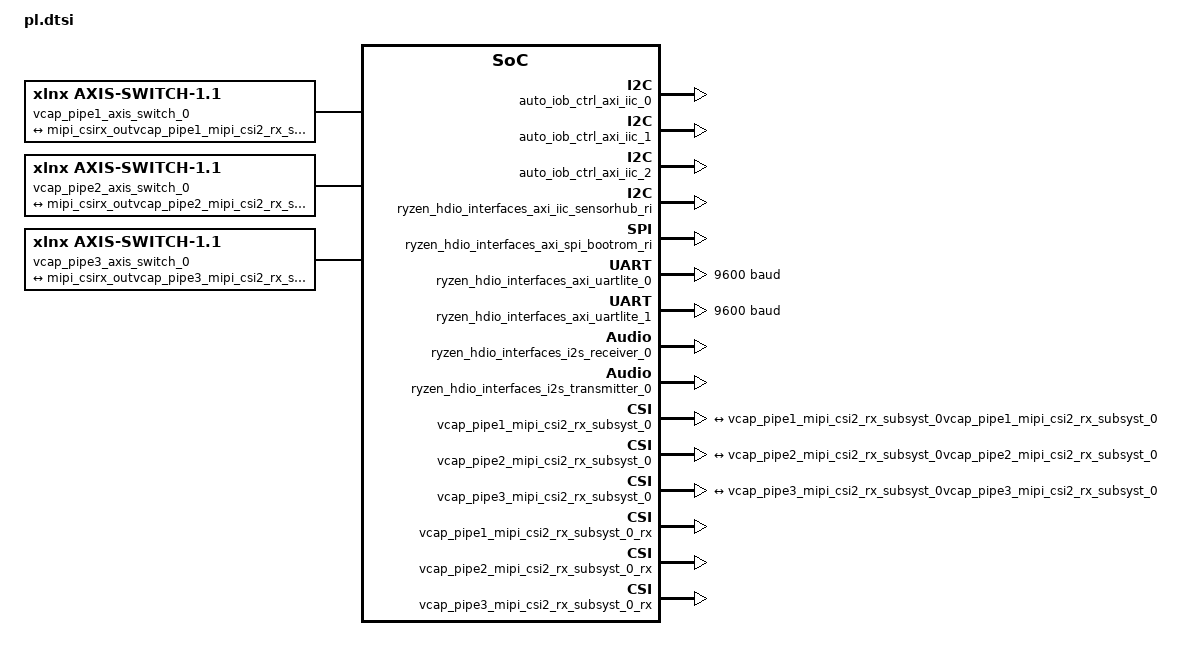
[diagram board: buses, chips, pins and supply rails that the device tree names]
/dts-v1/;
/plugin/;
&fpga {
	firmware-name = "versal_hexcam_20232_1_pld.pdi";
	misc_clk_2: misc_clk_2 {
		compatible = "fixed-clock";
		clock-frequency = <249997499>;
		#clock-cells = <0>;
	};
	misc_clk_0: misc_clk_0 {
		compatible = "fixed-clock";
		clock-frequency = <99999000>;
		#clock-cells = <0>;
	};
	misc_clk_4: misc_clk_4 {
		compatible = "fixed-clock";
		clock-frequency = <125000000>;
		#clock-cells = <0>;
	};
	misc_clk_1: misc_clk_1 {
		compatible = "fixed-clock";
		clock-frequency = <199998000>;
		#clock-cells = <0>;
	};
	misc_clk_3: misc_clk_3 {
		compatible = "fixed-clock";
		clock-frequency = <100000000>;
		#clock-cells = <0>;
	};
};

&amba {
	axi_intc_0: interrupt-controller@b01b0000 {
		#interrupt-cells = <2>;
		interrupts = < 0 143 4 >;
		xlnx,sense-of-irq-edge-type = "Rising";
		xlnx,edk-special = "INTR_CTRL";
		xlnx,kind-of-intr = <0x300>;
		xlnx,kind-of-edge = <0xffffffff>;
		xlnx,irq-is-level = <1>;
		xlnx,has-ivr = <1>;
		compatible = "xlnx,axi-intc-4.1" , "xlnx,xps-intc-1.00.a";
		xlnx,disable-synchronizers = <0>;
		xlnx,kind-of-lvl = <0xffffffff>;
		xlnx,ivar-reset-value = <0x10>;
		xlnx,irq-active = <0x1>;
		interrupt-parent = <&gic>;
		xlnx,en-cascade-mode = <0>;
		xlnx,ip-name = "axi_intc";
		xlnx,has-ilr = <0>;
		reg = <0x0 0xb01b0000 0x0 0x10000>;
		xlnx,addr-width = <0x20>;
		clocks = <&misc_clk_0>;
		xlnx,s-axi-aclk-freq-mhz = <0x5f5dd18>;
		xlnx,num-sw-intr = <0>;
		xlnx,irq-connection = <1>;
		xlnx,num-intr-inputs = <0x16>;
		xlnx,has-sie = <1>;
		xlnx,enable-async = <0>;
		xlnx,has-cie = <1>;
		xlnx,num-sync-ff = <2>;
		xlnx,edk-iptype = "PERIPHERAL";
		xlnx,mb-clk-not-connected = <1>;
		xlnx,has-ipr = <1>;
		xlnx,sense-of-irq-level-type = "Active_High";
		xlnx,cascade-master = <0>;
		xlnx,processor-clk-freq-mhz = <100>;
		xlnx,is-fast = <0x0>;
		clock-names = "s_axi_aclk";
		xlnx,has-fast = <0>;
		xlnx,ivar-rst-val = <0x10>;
		interrupt-controller;
		interrupt-names = "irq";
		xlnx,async-intr = <0xffcffff8>;
		xlnx,name = "axi_intc_0";
	};
	auto_iob_ctrl_axi_gpio_0: gpio@b0130000 {
		xlnx,gpio-board-interface = "Custom";
		compatible = "xlnx,axi-gpio-2.0" , "xlnx,xps-gpio-1.00.a";
		xlnx,all-outputs = <0>;
		#gpio-cells = <2>;
		xlnx,gpio-width = <24>;
		xlnx,dout-default = <0x24042>;
		xlnx,is-dual = <0>;
		xlnx,ip-name = "axi_gpio";
		xlnx,tri-default-2 = <0xffffffff>;
		reg = <0x0 0xb0130000 0x0 0x10000>;
		xlnx,all-inputs-2 = <0>;
		clocks = <&misc_clk_0>;
		xlnx,all-outputs-2 = <0>;
		gpio-controller;
		xlnx,interrupt-present = <0>;
		xlnx,gpio2-board-interface = "Custom";
		xlnx,edk-iptype = "PERIPHERAL";
		xlnx,dout-default-2 = <0x0>;
		xlnx,gpio2-width = <32>;
		clock-names = "s_axi_aclk";
		xlnx,tri-default = <0xf00>;
		xlnx,name = "auto_iob_ctrl_axi_gpio_0";
		xlnx,all-inputs = <0>;
	};
	auto_iob_ctrl_axi_gpio_1: gpio@b0140000 {
		xlnx,gpio-board-interface = "Custom";
		compatible = "xlnx,axi-gpio-2.0" , "xlnx,xps-gpio-1.00.a";
		xlnx,all-outputs = <0>;
		#gpio-cells = <2>;
		xlnx,gpio-width = <5>;
		xlnx,dout-default = <0x0>;
		xlnx,is-dual = <0>;
		xlnx,ip-name = "axi_gpio";
		xlnx,tri-default-2 = <0xffffffff>;
		reg = <0x0 0xb0140000 0x0 0x10000>;
		xlnx,all-inputs-2 = <0>;
		clocks = <&misc_clk_0>;
		xlnx,all-outputs-2 = <0>;
		gpio-controller;
		xlnx,interrupt-present = <0>;
		xlnx,gpio2-board-interface = "Custom";
		xlnx,edk-iptype = "PERIPHERAL";
		xlnx,dout-default-2 = <0x0>;
		xlnx,gpio2-width = <32>;
		clock-names = "s_axi_aclk";
		xlnx,tri-default = <0xffffffff>;
		xlnx,name = "auto_iob_ctrl_axi_gpio_1";
		xlnx,all-inputs = <0>;
	};
	auto_iob_ctrl_axi_gpio_2: gpio@b0150000 {
		xlnx,gpio-board-interface = "Custom";
		compatible = "xlnx,axi-gpio-2.0" , "xlnx,xps-gpio-1.00.a";
		xlnx,all-outputs = <0>;
		#gpio-cells = <2>;
		xlnx,gpio-width = <5>;
		xlnx,dout-default = <0x0>;
		xlnx,is-dual = <0>;
		xlnx,ip-name = "axi_gpio";
		xlnx,tri-default-2 = <0xffffffff>;
		reg = <0x0 0xb0150000 0x0 0x10000>;
		xlnx,all-inputs-2 = <0>;
		clocks = <&misc_clk_0>;
		xlnx,all-outputs-2 = <0>;
		gpio-controller;
		xlnx,interrupt-present = <0>;
		xlnx,gpio2-board-interface = "Custom";
		xlnx,edk-iptype = "PERIPHERAL";
		xlnx,dout-default-2 = <0x0>;
		xlnx,gpio2-width = <32>;
		clock-names = "s_axi_aclk";
		xlnx,tri-default = <0xffffffff>;
		xlnx,name = "auto_iob_ctrl_axi_gpio_2";
		xlnx,all-inputs = <0>;
	};
	auto_iob_ctrl_axi_gpio_3: gpio@b0160000 {
		xlnx,gpio-board-interface = "Custom";
		compatible = "xlnx,axi-gpio-2.0" , "xlnx,xps-gpio-1.00.a";
		xlnx,all-outputs = <0>;
		#gpio-cells = <2>;
		xlnx,gpio-width = <6>;
		xlnx,dout-default = <0x0>;
		xlnx,is-dual = <0>;
		xlnx,ip-name = "axi_gpio";
		xlnx,tri-default-2 = <0xffffffff>;
		reg = <0x0 0xb0160000 0x0 0x10000>;
		xlnx,all-inputs-2 = <0>;
		clocks = <&misc_clk_0>;
		xlnx,all-outputs-2 = <0>;
		gpio-controller;
		xlnx,interrupt-present = <0>;
		xlnx,gpio2-board-interface = "Custom";
		xlnx,edk-iptype = "PERIPHERAL";
		xlnx,dout-default-2 = <0x0>;
		xlnx,gpio2-width = <32>;
		clock-names = "s_axi_aclk";
		xlnx,tri-default = <0xffffffff>;
		xlnx,name = "auto_iob_ctrl_axi_gpio_3";
		xlnx,all-inputs = <0>;
	};
	auto_iob_ctrl_axi_iic_0: i2c@b0170000 {
		interrupts = < 0 2 >;
		xlnx,iic-freq-khz = <100>;
		compatible = "xlnx,axi-iic-2.1" , "xlnx,xps-iic-2.00.a";
		xlnx,scl-inertial-delay = <0>;
		interrupt-parent = <&axi_intc_0>;
		xlnx,ip-name = "axi_iic";
		xlnx,disable-setup-violation-check = <0>;
		reg = <0x0 0xb0170000 0x0 0x10000>;
		clocks = <&misc_clk_0>;
		xlnx,gpo-width = <1>;
		xlnx,edk-iptype = "PERIPHERAL";
		xlnx,static-timing-reg-width = <0>;
		xlnx,sda-level = <1>;
		clock-names = "s_axi_aclk";
		xlnx,ten-bit-adr = <0>;
		xlnx,default-value = <0x0>;
		interrupt-names = "iic2intc_irpt";
		xlnx,iic-board-interface = "Custom";
		xlnx,timing-reg-width = <32>;
		xlnx,iic-freq = <100000>;
		xlnx,smbus-pmbus-host = <0>;
		xlnx,name = "auto_iob_ctrl_axi_iic_0";
		xlnx,axi-aclk-freq-mhz = <0x5f5dd18>;
		xlnx,sda-inertial-delay = <0>;
	};
	auto_iob_ctrl_axi_iic_1: i2c@b0180000 {
		interrupts = < 1 2 >;
		xlnx,iic-freq-khz = <100>;
		compatible = "xlnx,axi-iic-2.1" , "xlnx,xps-iic-2.00.a";
		xlnx,scl-inertial-delay = <0>;
		interrupt-parent = <&axi_intc_0>;
		xlnx,ip-name = "axi_iic";
		xlnx,disable-setup-violation-check = <0>;
		reg = <0x0 0xb0180000 0x0 0x10000>;
		clocks = <&misc_clk_0>;
		xlnx,gpo-width = <1>;
		xlnx,edk-iptype = "PERIPHERAL";
		xlnx,static-timing-reg-width = <0>;
		xlnx,sda-level = <1>;
		clock-names = "s_axi_aclk";
		xlnx,ten-bit-adr = <0>;
		xlnx,default-value = <0x0>;
		interrupt-names = "iic2intc_irpt";
		xlnx,iic-board-interface = "Custom";
		xlnx,timing-reg-width = <32>;
		xlnx,iic-freq = <100000>;
		xlnx,smbus-pmbus-host = <0>;
		xlnx,name = "auto_iob_ctrl_axi_iic_1";
		xlnx,axi-aclk-freq-mhz = <0x5f5dd18>;
		xlnx,sda-inertial-delay = <0>;
	};
	auto_iob_ctrl_axi_iic_2: i2c@b0190000 {
		interrupts = < 2 2 >;
		xlnx,iic-freq-khz = <100>;
		compatible = "xlnx,axi-iic-2.1" , "xlnx,xps-iic-2.00.a";
		xlnx,scl-inertial-delay = <0>;
		interrupt-parent = <&axi_intc_0>;
		xlnx,ip-name = "axi_iic";
		xlnx,disable-setup-violation-check = <0>;
		reg = <0x0 0xb0190000 0x0 0x10000>;
		clocks = <&misc_clk_0>;
		xlnx,gpo-width = <1>;
		xlnx,edk-iptype = "PERIPHERAL";
		xlnx,static-timing-reg-width = <0>;
		xlnx,sda-level = <1>;
		clock-names = "s_axi_aclk";
		xlnx,ten-bit-adr = <0>;
		xlnx,default-value = <0x0>;
		interrupt-names = "iic2intc_irpt";
		xlnx,iic-board-interface = "Custom";
		xlnx,timing-reg-width = <32>;
		xlnx,iic-freq = <100000>;
		xlnx,smbus-pmbus-host = <0>;
		xlnx,name = "auto_iob_ctrl_axi_iic_2";
		xlnx,axi-aclk-freq-mhz = <0x5f5dd18>;
		xlnx,sda-inertial-delay = <0>;
	};
	axi_gpio_rst: gpio@b01a0000 {
		xlnx,gpio-board-interface = "Custom";
		compatible = "xlnx,axi-gpio-2.0" , "xlnx,xps-gpio-1.00.a";
		xlnx,all-outputs = <1>;
		#gpio-cells = <2>;
		xlnx,gpio-width = <32>;
		xlnx,dout-default = <0xffffffff>;
		xlnx,is-dual = <0>;
		xlnx,ip-name = "axi_gpio";
		xlnx,tri-default-2 = <0xffffffff>;
		reg = <0x0 0xb01a0000 0x0 0x10000>;
		xlnx,all-inputs-2 = <0>;
		clocks = <&misc_clk_0>;
		xlnx,all-outputs-2 = <0>;
		gpio-controller;
		xlnx,interrupt-present = <0>;
		xlnx,gpio2-board-interface = "Custom";
		xlnx,edk-iptype = "PERIPHERAL";
		xlnx,dout-default-2 = <0x0>;
		xlnx,gpio2-width = <32>;
		clock-names = "s_axi_aclk";
		xlnx,tri-default = <0xffffffff>;
		xlnx,name = "axi_gpio_rst";
		xlnx,all-inputs = <0>;
	};
	messaging_axi_bram_ctrl_0: messaging_axi_bram_ctrl_0@80100000000 {
		xlnx,protocol = "AXI4";
		xlnx,edk-special = "BRAM_CTRL";
		compatible = "xlnx,axi-bram-ctrl-4.1" , "xlnx,axi-bram-ctrl";
		xlnx,ecc-onoff-reset-value = <0>;
		xlnx,ecc-type = <0>;
		xlnx,rd-cmd-optimization = <0>;
		xlnx,memory-depth = <2048>;
		xlnx,use-ecc = <0>;
		xlnx,fault-inject = <0>;
		xlnx,ip-name = "axi_bram_ctrl";
		reg = <0x00000801 0x00000000 0x0 0x2000>;
		xlnx,bmg-instance = "EXTERNAL";
		clocks = <&misc_clk_0>;
		xlnx,s-axi-ctrl-addr-width = <32>;
		xlnx,read-latency = <1>;
		xlnx,id-width = <0>;
		xlnx,s-axi-supports-narrow-burst = <0>;
		xlnx,supports-narrow-burst = <0>;
		xlnx,single-port-bram = <1>;
		xlnx,ecc = <0>;
		xlnx,edk-iptype = "PERIPHERAL";
		clock-names = "s_axi_aclk";
		xlnx,data-width = <32>;
		xlnx,bram-addr-width = <11>;
		xlnx,bram-inst-mode = "EXTERNAL";
		xlnx,s-axi-ctrl-data-width = <32>;
		xlnx,mem-depth = <2048>;
		xlnx,s-axi-id-width = <1>;
		xlnx,name = "messaging_axi_bram_ctrl_0";
	};
	messaging_axi_bram_ctrl_1: messaging_axi_bram_ctrl_1@80100002000 {
		xlnx,protocol = "AXI4";
		xlnx,edk-special = "BRAM_CTRL";
		compatible = "xlnx,axi-bram-ctrl-4.1" , "xlnx,axi-bram-ctrl";
		xlnx,ecc-onoff-reset-value = <0>;
		xlnx,ecc-type = <0>;
		xlnx,rd-cmd-optimization = <0>;
		xlnx,memory-depth = <2048>;
		xlnx,use-ecc = <0>;
		xlnx,fault-inject = <0>;
		xlnx,ip-name = "axi_bram_ctrl";
		reg = <0x00000801 0x00002000 0x0 0x2000>;
		xlnx,bmg-instance = "EXTERNAL";
		clocks = <&misc_clk_0>;
		xlnx,s-axi-ctrl-addr-width = <32>;
		xlnx,read-latency = <1>;
		xlnx,id-width = <0>;
		xlnx,s-axi-supports-narrow-burst = <0>;
		xlnx,supports-narrow-burst = <0>;
		xlnx,single-port-bram = <1>;
		xlnx,ecc = <0>;
		xlnx,edk-iptype = "PERIPHERAL";
		clock-names = "s_axi_aclk";
		xlnx,data-width = <32>;
		xlnx,bram-addr-width = <11>;
		xlnx,bram-inst-mode = "EXTERNAL";
		xlnx,s-axi-ctrl-data-width = <32>;
		xlnx,mem-depth = <2048>;
		xlnx,s-axi-id-width = <1>;
		xlnx,name = "messaging_axi_bram_ctrl_1";
	};
	messaging_axi_gpio_0: gpio@80100005000 {
		xlnx,gpio-board-interface = "Custom";
		compatible = "xlnx,axi-gpio-2.0" , "xlnx,xps-gpio-1.00.a";
		xlnx,all-outputs = <1>;
		#gpio-cells = <2>;
		xlnx,gpio-width = <2>;
		xlnx,dout-default = <0x0>;
		xlnx,is-dual = <0>;
		xlnx,ip-name = "axi_gpio";
		xlnx,tri-default-2 = <0xffffffff>;
		reg = <0x00000801 0x00005000 0x0 0x1000>;
		xlnx,all-inputs-2 = <0>;
		clocks = <&misc_clk_0>;
		xlnx,all-outputs-2 = <0>;
		gpio-controller;
		xlnx,interrupt-present = <0>;
		xlnx,gpio2-board-interface = "Custom";
		xlnx,edk-iptype = "PERIPHERAL";
		xlnx,dout-default-2 = <0x0>;
		xlnx,gpio2-width = <32>;
		clock-names = "s_axi_aclk";
		xlnx,tri-default = <0xffffffff>;
		xlnx,name = "messaging_axi_gpio_0";
		xlnx,all-inputs = <0>;
	};
	messaging_axi_gpio_1: gpio@80100004000 {
		xlnx,gpio-board-interface = "Custom";
		compatible = "xlnx,axi-gpio-2.0" , "xlnx,xps-gpio-1.00.a";
		xlnx,all-outputs = <1>;
		#gpio-cells = <2>;
		xlnx,gpio-width = <2>;
		xlnx,dout-default = <0x0>;
		xlnx,is-dual = <0>;
		xlnx,ip-name = "axi_gpio";
		xlnx,tri-default-2 = <0xffffffff>;
		reg = <0x00000801 0x00004000 0x0 0x1000>;
		xlnx,all-inputs-2 = <0>;
		clocks = <&misc_clk_0>;
		xlnx,all-outputs-2 = <0>;
		gpio-controller;
		xlnx,interrupt-present = <0>;
		xlnx,gpio2-board-interface = "Custom";
		xlnx,edk-iptype = "PERIPHERAL";
		xlnx,dout-default-2 = <0x0>;
		xlnx,gpio2-width = <32>;
		clock-names = "s_axi_aclk";
		xlnx,tri-default = <0xffffffff>;
		xlnx,name = "messaging_axi_gpio_1";
		xlnx,all-inputs = <0>;
	};
	ryzen_hdio_interfaces_axi_gpio_0: gpio@b01c0000 {
		xlnx,gpio-board-interface = "Custom";
		compatible = "xlnx,axi-gpio-2.0" , "xlnx,xps-gpio-1.00.a";
		xlnx,all-outputs = <0>;
		#gpio-cells = <2>;
		xlnx,gpio-width = <2>;
		xlnx,dout-default = <0x0>;
		xlnx,is-dual = <0>;
		xlnx,ip-name = "axi_gpio";
		xlnx,tri-default-2 = <0xffffffff>;
		reg = <0x0 0xb01c0000 0x0 0x10000>;
		xlnx,all-inputs-2 = <0>;
		clocks = <&misc_clk_0>;
		xlnx,all-outputs-2 = <0>;
		gpio-controller;
		xlnx,interrupt-present = <0>;
		xlnx,gpio2-board-interface = "Custom";
		xlnx,edk-iptype = "PERIPHERAL";
		xlnx,dout-default-2 = <0x0>;
		xlnx,gpio2-width = <32>;
		clock-names = "s_axi_aclk";
		xlnx,tri-default = <0xffffffff>;
		xlnx,name = "ryzen_hdio_interfaces_axi_gpio_0";
		xlnx,all-inputs = <0>;
	};
	ryzen_hdio_interfaces_axi_gpio_bootrom_ri: gpio@b01d0000 {
		xlnx,gpio-board-interface = "Custom";
		compatible = "xlnx,axi-gpio-2.0" , "xlnx,xps-gpio-1.00.a";
		xlnx,all-outputs = <0>;
		#gpio-cells = <2>;
		xlnx,gpio-width = <1>;
		xlnx,dout-default = <0x0>;
		xlnx,is-dual = <0>;
		xlnx,ip-name = "axi_gpio";
		xlnx,tri-default-2 = <0xffffffff>;
		reg = <0x0 0xb01d0000 0x0 0x10000>;
		xlnx,all-inputs-2 = <0>;
		clocks = <&misc_clk_0>;
		xlnx,all-outputs-2 = <0>;
		gpio-controller;
		xlnx,interrupt-present = <0>;
		xlnx,gpio2-board-interface = "Custom";
		xlnx,edk-iptype = "PERIPHERAL";
		xlnx,dout-default-2 = <0x0>;
		xlnx,gpio2-width = <32>;
		clock-names = "s_axi_aclk";
		xlnx,tri-default = <0xffffffff>;
		xlnx,name = "ryzen_hdio_interfaces_axi_gpio_bootrom_ri";
		xlnx,all-inputs = <0>;
	};
	ryzen_hdio_interfaces_axi_gpio_sensorhub_ri: gpio@b01e0000 {
		xlnx,gpio-board-interface = "Custom";
		compatible = "xlnx,axi-gpio-2.0" , "xlnx,xps-gpio-1.00.a";
		xlnx,all-outputs = <0>;
		#gpio-cells = <2>;
		xlnx,gpio-width = <1>;
		xlnx,dout-default = <0x0>;
		xlnx,is-dual = <0>;
		xlnx,ip-name = "axi_gpio";
		xlnx,tri-default-2 = <0xffffffff>;
		reg = <0x0 0xb01e0000 0x0 0x10000>;
		xlnx,all-inputs-2 = <0>;
		clocks = <&misc_clk_0>;
		xlnx,all-outputs-2 = <0>;
		gpio-controller;
		xlnx,interrupt-present = <0>;
		xlnx,gpio2-board-interface = "Custom";
		xlnx,edk-iptype = "PERIPHERAL";
		xlnx,dout-default-2 = <0x0>;
		xlnx,gpio2-width = <32>;
		clock-names = "s_axi_aclk";
		xlnx,tri-default = <0xffffffff>;
		xlnx,name = "ryzen_hdio_interfaces_axi_gpio_sensorhub_ri";
		xlnx,all-inputs = <0>;
	};
	ryzen_hdio_interfaces_axi_iic_sensorhub_ri: i2c@b01f0000 {
		xlnx,iic-freq-khz = <100>;
		compatible = "xlnx,axi-iic-2.1" , "xlnx,xps-iic-2.00.a";
		xlnx,scl-inertial-delay = <0>;
		xlnx,ip-name = "axi_iic";
		xlnx,disable-setup-violation-check = <0>;
		reg = <0x0 0xb01f0000 0x0 0x10000>;
		clocks = <&misc_clk_0>;
		xlnx,gpo-width = <1>;
		xlnx,edk-iptype = "PERIPHERAL";
		xlnx,static-timing-reg-width = <0>;
		xlnx,sda-level = <1>;
		clock-names = "s_axi_aclk";
		xlnx,ten-bit-adr = <0>;
		xlnx,default-value = <0x0>;
		xlnx,iic-board-interface = "Custom";
		xlnx,timing-reg-width = <32>;
		xlnx,iic-freq = <100000>;
		xlnx,smbus-pmbus-host = <0>;
		xlnx,name = "ryzen_hdio_interfaces_axi_iic_sensorhub_ri";
		xlnx,axi-aclk-freq-mhz = <0x5f5dd18>;
		xlnx,sda-inertial-delay = <0>;
	};
	ryzen_hdio_interfaces_axi_spi_bootrom_ri: axi_quad_spi@b0210000 {
		xlnx,select-xpm = <0>;
		compatible = "xlnx,axi-quad-spi-3.2" , "xlnx,xps-spi-2.00.a";
		xlnx,lsb-stup = <0>;
		xlnx,num-ss-bits = <0x1>;
		xlnx,hasfifos = <1>;
		xlnx,xip-mode = <0>;
		xlnx,use-startup-ext = <0>;
		xlnx,s-axi4-addr-width = <24>;
		xlnx,byte-level-interrupt-en = <0>;
		num-cs = <0x1>;
		xlnx,xip-perf-mode = <1>;
		xlnx,sck-ratio = <16>;
		xlnx,s-axi4-id-width = <4>;
		fifo-size = <16>;
		xlnx,multiples16 = <1>;
		xlnx,master-mode = <1>;
		xlnx,shared-startup = <0>;
		xlnx,ip-name = "axi_quad_spi";
		xlnx,qspi-board-interface = "Custom";
		reg = <0x0 0xb0210000 0x0 0x10000>;
		xlnx,dual-quad-mode = <0>;
		xlnx,new-seq-en = <1>;
		bits-per-word = <8>;
		clocks = <&misc_clk_0>, <&misc_clk_0>;
		xlnx,num-transfer-bits = <8>;
		xlnx,spi-memory = <1>;
		xlnx,s-axi4-data-width = <32>;
		xlnx,edk-iptype = "PERIPHERAL";
		xlnx,slaveonly = <0>;
		xlnx,use-startup-int = <0>;
		xlnx,use-startup = <0>;
		xlnx,type-of-axi4-interface = <0>;
		xlnx,async-clk = <0>;
		xlnx,spi-mode = <0>;
		xlnx,sck-ratio1 = <1>;
		xlnx,fifo-depth = <16>;
		clock-names = "ext_spi_clk" , "s_axi_aclk";
		xlnx,uc-family = <0>;
		xlnx,spi-mem-addr-bits = <24>;
		xlnx,axi-interface = <0>;
		xlnx,Axi4-address = <0>;
		xlnx,fifo-included = <1>;
		xlnx,sub-family = "versal";
		xlnx,name = "ryzen_hdio_interfaces_axi_spi_bootrom_ri";
	};
	ryzen_hdio_interfaces_axi_uartlite_0: serial@b0220000 {
		compatible = "xlnx,axi-uartlite-2.0" , "xlnx,xps-uartlite-1.00.a";
		xlnx,uartlite-board-interface = "Custom";
		xlnx,s-axi-aclk-freq-hz-d = <0x5f5dd18>;
		xlnx,ip-name = "axi_uartlite";
		reg = <0x0 0xb0220000 0x0 0x10000>;
		xlnx,baudrate = <9600>;
		clocks = <&misc_clk_0>;
		current-speed = <9600>;
		xlnx,use-parity = <0>;
		xlnx,edk-iptype = "PERIPHERAL";
		xlnx,odd-parity = <0>;
		clock-names = "s_axi_aclk";
		xlnx,name = "ryzen_hdio_interfaces_axi_uartlite_0";
		xlnx,data-bits = <8>;
		xlnx,parity = "No_Parity";
	};
	ryzen_hdio_interfaces_axi_uartlite_1: serial@b0230000 {
		compatible = "xlnx,axi-uartlite-2.0" , "xlnx,xps-uartlite-1.00.a";
		xlnx,uartlite-board-interface = "Custom";
		xlnx,s-axi-aclk-freq-hz-d = <0x5f5dd18>;
		xlnx,ip-name = "axi_uartlite";
		reg = <0x0 0xb0230000 0x0 0x10000>;
		xlnx,baudrate = <9600>;
		clocks = <&misc_clk_0>;
		current-speed = <9600>;
		xlnx,use-parity = <0>;
		xlnx,edk-iptype = "PERIPHERAL";
		xlnx,odd-parity = <0>;
		clock-names = "s_axi_aclk";
		xlnx,name = "ryzen_hdio_interfaces_axi_uartlite_1";
		xlnx,data-bits = <8>;
		xlnx,parity = "No_Parity";
	};
	ryzen_hdio_interfaces_i2s_receiver_0: i2s_receiver@b0010000 {
		aud_mclk = <99999000>;
		interrupts = < 18 2 >;
		compatible = "xlnx,i2s-receiver-1.0" , "xlnx,i2s-receiver-1.0";
		xlnx,dwidth = <0x18>;
		xlnx,depth = <0x80>;
		interrupt-parent = <&axi_intc_0>;
		xlnx,ip-name = "i2s_receiver";
		reg = <0x0 0xb0010000 0x0 0x10000>;
		clocks = <&misc_clk_0>, <&misc_clk_0>, <&misc_clk_0>;
		xlnx,num-channels = <0x1>;
		xlnx,i2srx-board-interface = "Custom";
		xlnx,edk-iptype = "PERIPHERAL";
		xlnx,is-master = <1>;
		clock-names = "aud_mclk" , "m_axis_aud_aclk" , "s_axi_ctrl_aclk";
		xlnx,32bit-lr = <0>;
		interrupt-names = "irq";
		xlnx,name = "ryzen_hdio_interfaces_i2s_receiver_0";
	};
	ryzen_hdio_interfaces_i2s_transmitter_0: i2s_transmitter@b0020000 {
		aud_mclk = <99999000>;
		interrupts = < 19 2 >;
		compatible = "xlnx,i2s-transmitter-1.0" , "xlnx,i2s-transmitter-1.0";
		xlnx,dwidth = <0x18>;
		xlnx,depth = <0x80>;
		interrupt-parent = <&axi_intc_0>;
		xlnx,ip-name = "i2s_transmitter";
		reg = <0x0 0xb0020000 0x0 0x10000>;
		clocks = <&misc_clk_0>, <&misc_clk_0>, <&misc_clk_0>;
		xlnx,num-channels = <0x1>;
		xlnx,edk-iptype = "PERIPHERAL";
		xlnx,is-master = <1>;
		xlnx,i2stx-board-interface = "Custom";
		clock-names = "aud_mclk" , "s_axi_ctrl_aclk" , "s_axis_aud_aclk";
		xlnx,32bit-lr = <0>;
		interrupt-names = "irq";
		xlnx,name = "ryzen_hdio_interfaces_i2s_transmitter_0";
	};
	vcap_pipe1_mipi_csi2_rx_subsyst_0: mipi_csi2_rx_subsystem@b0000000 {
		xlnx,data-lane2-byte = "All_Byte";
		xlnx,dpy-en-reg-if = <1>;
		xlnx,cmn-vc = <4>;
		xlnx,dphy-lanes = <3>;
		xlnx,ip-name = "mipi_csi2_rx_subsystem";
		reg = <0x0 0xb0000000 0x0 0x2000>;
		xlnx,vfb-tu-width = <1>;
		xlnx,ppc = <4>;
		xlnx,csi-buf-depth = <2048>;
		xlnx,exdes-fmc = "LI-IMX274MIPI-FMC , V1.0 , Single , Sensor";
		xlnx,supportlevel = <1>;
		xlnx,clk-lane-io-loc-name = "None";
		xlnx,max-lanes = <3>;
		xlnx,is-versal;
		xlnx,cmn-inc-iic = <0>;
		xlnx,clk-lane-io-loc = "None";
		xlnx,esc-timeout = <25600>;
		interrupt-names = "csirxss_csi_irq";
		xlnx,cmn-inc-vfb;
		xlnx,axis-tuser-width = <96>;
		compatible = "xlnx,mipi-csi2-rx-subsystem-6.0" , "xlnx,mipi-csi2-rx-subsystem-5.0";
		xlnx,en-active-lanes;
		xlnx,idly-tap = <1>;
		dphy-present = <0>;
		xlnx,cmn-num-pixels = <4>;
		xlnx,cmn-proj-family = <0>;
		xlnx,csi2rx-dbg = <0>;
		xlnx,fifo-rd-en-control;
		xlnx,vfb;
		interrupt-parent = <&axi_intc_0>;
		xlnx,data-lane1-io-loc-name = "None";
		xlnx,hs-timeout = <65541>;
		xlnx,data-lane3-io-loc-name = "None";
		xlnx,ext-mmcm = <0>;
		xlnx,data-lane1-byte = "All_Byte";
		xlnx,master-riu;
		xlnx,cal-mode = "NONE";
		rxphy-connected = <&vcap_pipe1_mipi_csi2_rx_subsyst_0_phy>;
		xlnx,mipi-rx-phy-mode = <0>;
		xlnx,data-lane0-io-position = <2>;
		xlnx,exdes-board = "VEK280";
		xlnx,data-lane2-io-position = <6>;
		xlnx,vc = <4>;
		xlnx,en-vcx = <0>;
		xlnx,name = "vcap_pipe1_mipi_csi2_rx_subsyst_0";
		xlnx,csi-emb-non-img = <0>;
		interrupts = < 3 2 >;
		xlnx,dphyrx-board-interface = "Custom";
		xlnx,data-lane3-io-loc = "None";
		xlnx,clock-mask = <39>;
		xlnx,hs-settle-ns = <16>;
		xlnx,en-cnts-byte-clk;
		clocks = <&misc_clk_1>, <&misc_clk_0>, <&misc_clk_2>;
		xlnx,data-lane2-io-loc = "None";
		xlnx,mipi-slv-int = <0>;
		xlnx,is-ksb;
		xlnx,cmn-fifo-rd-en-cntrl;
		xlnx,data-lane3-byte = "All_Byte";
		xlnx,stretch-line-rate = <4500>;
		xlnx,phy-mode = "CPHY";
		xlnx,axis-tdest-width = <4>;
		xlnx,en-csi-v2 = <0>;
		xlnx,edk-iptype = "PERIPHERAL";
		xlnx,init = <100000>;
		xlnx,cmn-pxl-format = <0x18>;
		xlnx,int-qor-check = <0>;
		clock-names = "dphy_clk_200M" , "lite_aclk" , "video_aclk";
		xlnx,data-lane1-io-loc = "None";
		xlnx,data-lane0-byte = "All_Byte";
		xlnx,ooc-vid-clk = <0x65b710>;
		csirx-present = <1>;
		xlnx,yuv420-buf-dpth = <128>;
		xlnx,hp-io-bank-selection = <64>;
		xlnx,idly-group-name = "mipi_csi2rx_idly_group";
		xlnx,lprx-disable-extport = <0>;
		csirx-connected = <&vcap_pipe1_mipi_csi2_rx_subsyst_0_rx>;
		xlnx,highaddr = <0xb0001fff>;
		xlnx,cmn-num-lanes = <3>;
		xlnx,exdes-config = "MIPI_Video_Pipe_Camera_to_Display";
		xlnx,exdesboard-version = <2>;
		xlnx,dphy-preset = "CSI2RX_XLNX";
		xlnx,data-lane0-io-loc-name = "None";
		xlnx,csi-pxl-format = <0x18>;
		xlnx,clk-lane-io-position = <0>;
		xlnx,data-lane2-io-loc-name = "None";
		xlnx,data-lane0-io-loc = "None";
		xlnx,inc-phy;
		xlnx,hs-line-rate = <800>;
		rxphy-present = <1>;
		xlnx,dpy-line-rate = <2500>;
		xlnx,csi-en-crc = <1>;
		xlnx,axis-tdata-width = <32>;
		xlnx,csi-controller-reg-if;
		xlnx,data-lane1-io-position = <4>;
		xlnx,dphy-mode = "SLAVE";
		xlnx,data-lane3-io-position = <8>;
		mipi_csi_portsvcap_pipe1_mipi_csi2_rx_subsyst_0: ports {
			#address-cells = <1>;
			#size-cells = <0>;
			mipi_csi_port1vcap_pipe1_mipi_csi2_rx_subsyst_0: port@1 {
				xlnx,video-width = <8>;
				reg = <1>;
				xlnx,video-format = <12>;
				xlnx,cfa-pattern = "rggb";
				mipi_csirx_outvcap_pipe1_mipi_csi2_rx_subsyst_0: endpoint {
					remote-endpoint = <&vcap_pipe1_mipi_csi2_rx_subsyst_0vcap_pipe1_mipi_csi2_rx_subsyst_0>;
				};
			};
			mipi_csi_port0vcap_pipe1_mipi_csi2_rx_subsyst_0: port@0 {
				xlnx,video-width = <8>;
				reg = <0>;
				xlnx,video-format = <12>;
				xlnx,cfa-pattern = "rggb";
				mipi_csi_invcap_pipe1_mipi_csi2_rx_subsyst_0: endpoint {
					data-lanes = < 1 2 3 >;
				};
			};
		};
	};
	vcap_pipe1_v_frmbuf_wr_0: v_frmbuf_wr@b0030000 {
		xlnx,has-y-uv8 = <1>;
		reset-gpios = <&axi_gpio_rst 6 1>;
		xlnx,max-height = <2160>;
		xlnx,has-bgra8 = <0>;
		xlnx,has-rgba8 = <0>;
		xlnx,ip-name = "v_frmbuf_wr";
		reg = <0x0 0xb0030000 0x0 0x10000>;
		xlnx,s-axi-ctrl-addr-width = <0x7>;
		xlnx,pixels-per-clock = <4>;
		xlnx,samples-per-clock = <4>;
		xlnx,max-nr-planes = <2>;
		xlnx,has-bgr8 = <1>;
		xlnx,has-rgb8 = <1>;
		xlnx,has-y-uv8-420 = <0>;
		xlnx,has-yuyv8 = <1>;
		xlnx,has-y-u-v8 = <0>;
		interrupt-names = "interrupt";
		compatible = "xlnx,v-frmbuf-wr-3.0" , "xlnx,axi-frmbuf-wr-v2.2";
		xlnx,max-width = <3840>;
		xlnx,has-rgb16 = <0>;
		xlnx,vid-formats = "rgb888" , "bgr888" , "xbgr8888" , "xrgb8888" , "uyvy" , "y8" , "vuy888" , "xvuy8888" , "yuyv" , "nv16";
		xlnx,has-bgrx8 = <1>;
		xlnx,has-rgbx8 = <1>;
		xlnx,has-rgbx10 = <0>;
		interrupt-parent = <&axi_intc_0>;
		xlnx,aximm-num-outstanding = <4>;
		xlnx,has-uyvy8 = <1>;
		xlnx,use-uram = <0>;
		xlnx,has-rgbx12 = <0>;
		xlnx,aximm-burst-length = <16>;
		xlnx,aximm-addr-width = <64>;
		xlnx,video-width = <8>;
		xlnx,max-cols = <3840>;
		xlnx,has-yuv8 = <1>;
		xlnx,has-y-uv10-420 = <0>;
		xlnx,has-yuva8 = <0>;
		xlnx,has-y-uv12-420 = <0>;
		xlnx,name = "vcap_pipe1_v_frmbuf_wr_0";
		interrupts = < 4 2 >;
		xlnx,has-y10 = <0>;
		xlnx,has-y-uv16-420 = <0>;
		xlnx,has-y12 = <0>;
		xlnx,has-alpha = <0>;
		xlnx,has-y-u-v10 = <0>;
		clocks = <&misc_clk_2>;
		xlnx,has-y16 = <0>;
		xlnx,dma-align = <32>;
		xlnx,has-y-u-v12 = <0>;
		xlnx,edk-iptype = "PERIPHERAL";
		xlnx,has-interlaced = <0>;
		xlnx,has-yuv16 = <0>;
		xlnx,has-yuvx8 = <1>;
		xlnx,is-tile-format = <0>;
		xlnx,dma-addr-width = <64>;
		clock-names = "ap_clk";
		xlnx,s-axi-ctrl-data-width = <0x20>;
		xlnx,has-y8 = <1>;
		xlnx,has-y-uv10 = <0>;
		xlnx,has-y-uv12 = <0>;
		xlnx,max-rows = <2160>;
		xlnx,has-yuvx10 = <0>;
		#dma-cells = <1>;
		xlnx,has-yuvx12 = <0>;
		xlnx,has-y-uv16 = <0>;
		xlnx,max-data-width = <8>;
		xlnx,has-y-u-v8-420 = <0>;
		xlnx,num-video-components = <3>;
		xlnx,aximm-data-width = <256>;
	};
	vcap_pipe1_v_frmbuf_wr_1: v_frmbuf_wr@b0040000 {
		xlnx,has-y-uv8 = <1>;
		reset-gpios = <&axi_gpio_rst 7 1>;
		xlnx,max-height = <2160>;
		xlnx,has-bgra8 = <0>;
		xlnx,has-rgba8 = <0>;
		xlnx,ip-name = "v_frmbuf_wr";
		reg = <0x0 0xb0040000 0x0 0x10000>;
		xlnx,s-axi-ctrl-addr-width = <0x7>;
		xlnx,pixels-per-clock = <4>;
		xlnx,samples-per-clock = <4>;
		xlnx,max-nr-planes = <2>;
		xlnx,has-bgr8 = <1>;
		xlnx,has-rgb8 = <1>;
		xlnx,has-y-uv8-420 = <0>;
		xlnx,has-yuyv8 = <1>;
		xlnx,has-y-u-v8 = <0>;
		interrupt-names = "interrupt";
		compatible = "xlnx,v-frmbuf-wr-3.0" , "xlnx,axi-frmbuf-wr-v2.2";
		xlnx,max-width = <3840>;
		xlnx,has-rgb16 = <0>;
		xlnx,vid-formats = "rgb888" , "bgr888" , "xbgr8888" , "xrgb8888" , "uyvy" , "y8" , "vuy888" , "xvuy8888" , "yuyv" , "nv16";
		xlnx,has-bgrx8 = <1>;
		xlnx,has-rgbx8 = <1>;
		xlnx,has-rgbx10 = <0>;
		interrupt-parent = <&axi_intc_0>;
		xlnx,aximm-num-outstanding = <4>;
		xlnx,has-uyvy8 = <1>;
		xlnx,use-uram = <0>;
		xlnx,has-rgbx12 = <0>;
		xlnx,aximm-burst-length = <16>;
		xlnx,aximm-addr-width = <64>;
		xlnx,video-width = <8>;
		xlnx,max-cols = <3840>;
		xlnx,has-yuv8 = <1>;
		xlnx,has-y-uv10-420 = <0>;
		xlnx,has-yuva8 = <0>;
		xlnx,has-y-uv12-420 = <0>;
		xlnx,name = "vcap_pipe1_v_frmbuf_wr_1";
		interrupts = < 5 2 >;
		xlnx,has-y10 = <0>;
		xlnx,has-y-uv16-420 = <0>;
		xlnx,has-y12 = <0>;
		xlnx,has-alpha = <0>;
		xlnx,has-y-u-v10 = <0>;
		clocks = <&misc_clk_2>;
		xlnx,has-y16 = <0>;
		xlnx,dma-align = <32>;
		xlnx,has-y-u-v12 = <0>;
		xlnx,edk-iptype = "PERIPHERAL";
		xlnx,has-interlaced = <0>;
		xlnx,has-yuv16 = <0>;
		xlnx,has-yuvx8 = <1>;
		xlnx,is-tile-format = <0>;
		xlnx,dma-addr-width = <64>;
		clock-names = "ap_clk";
		xlnx,s-axi-ctrl-data-width = <0x20>;
		xlnx,has-y8 = <1>;
		xlnx,has-y-uv10 = <0>;
		xlnx,has-y-uv12 = <0>;
		xlnx,max-rows = <2160>;
		xlnx,has-yuvx10 = <0>;
		#dma-cells = <1>;
		xlnx,has-yuvx12 = <0>;
		xlnx,has-y-uv16 = <0>;
		xlnx,max-data-width = <8>;
		xlnx,has-y-u-v8-420 = <0>;
		xlnx,num-video-components = <3>;
		xlnx,aximm-data-width = <256>;
	};
	vcap_pipe1_v_frmbuf_wr_2: v_frmbuf_wr@b0050000 {
		xlnx,has-y-uv8 = <1>;
		reset-gpios = <&axi_gpio_rst 8 1>;
		xlnx,max-height = <2160>;
		xlnx,has-bgra8 = <0>;
		xlnx,has-rgba8 = <0>;
		xlnx,ip-name = "v_frmbuf_wr";
		reg = <0x0 0xb0050000 0x0 0x10000>;
		xlnx,s-axi-ctrl-addr-width = <0x7>;
		xlnx,pixels-per-clock = <4>;
		xlnx,samples-per-clock = <4>;
		xlnx,max-nr-planes = <2>;
		xlnx,has-bgr8 = <1>;
		xlnx,has-rgb8 = <1>;
		xlnx,has-y-uv8-420 = <0>;
		xlnx,has-yuyv8 = <1>;
		xlnx,has-y-u-v8 = <0>;
		interrupt-names = "interrupt";
		compatible = "xlnx,v-frmbuf-wr-3.0" , "xlnx,axi-frmbuf-wr-v2.2";
		xlnx,max-width = <3840>;
		xlnx,has-rgb16 = <0>;
		xlnx,vid-formats = "rgb888" , "bgr888" , "xbgr8888" , "xrgb8888" , "uyvy" , "y8" , "vuy888" , "xvuy8888" , "yuyv" , "nv16";
		xlnx,has-bgrx8 = <1>;
		xlnx,has-rgbx8 = <1>;
		xlnx,has-rgbx10 = <0>;
		interrupt-parent = <&axi_intc_0>;
		xlnx,aximm-num-outstanding = <4>;
		xlnx,has-uyvy8 = <1>;
		xlnx,use-uram = <0>;
		xlnx,has-rgbx12 = <0>;
		xlnx,aximm-burst-length = <16>;
		xlnx,aximm-addr-width = <64>;
		xlnx,video-width = <8>;
		xlnx,max-cols = <3840>;
		xlnx,has-yuv8 = <1>;
		xlnx,has-y-uv10-420 = <0>;
		xlnx,has-yuva8 = <0>;
		xlnx,has-y-uv12-420 = <0>;
		xlnx,name = "vcap_pipe1_v_frmbuf_wr_2";
		interrupts = < 6 2 >;
		xlnx,has-y10 = <0>;
		xlnx,has-y-uv16-420 = <0>;
		xlnx,has-y12 = <0>;
		xlnx,has-alpha = <0>;
		xlnx,has-y-u-v10 = <0>;
		clocks = <&misc_clk_2>;
		xlnx,has-y16 = <0>;
		xlnx,dma-align = <32>;
		xlnx,has-y-u-v12 = <0>;
		xlnx,edk-iptype = "PERIPHERAL";
		xlnx,has-interlaced = <0>;
		xlnx,has-yuv16 = <0>;
		xlnx,has-yuvx8 = <1>;
		xlnx,is-tile-format = <0>;
		xlnx,dma-addr-width = <64>;
		clock-names = "ap_clk";
		xlnx,s-axi-ctrl-data-width = <0x20>;
		xlnx,has-y8 = <1>;
		xlnx,has-y-uv10 = <0>;
		xlnx,has-y-uv12 = <0>;
		xlnx,max-rows = <2160>;
		xlnx,has-yuvx10 = <0>;
		#dma-cells = <1>;
		xlnx,has-yuvx12 = <0>;
		xlnx,has-y-uv16 = <0>;
		xlnx,max-data-width = <8>;
		xlnx,has-y-u-v8-420 = <0>;
		xlnx,num-video-components = <3>;
		xlnx,aximm-data-width = <256>;
	};
	vcap_pipe1_v_frmbuf_wr_3: v_frmbuf_wr@b0060000 {
		xlnx,has-y-uv8 = <1>;
		reset-gpios = <&axi_gpio_rst 9 1>;
		xlnx,max-height = <2160>;
		xlnx,has-bgra8 = <0>;
		xlnx,has-rgba8 = <0>;
		xlnx,ip-name = "v_frmbuf_wr";
		reg = <0x0 0xb0060000 0x0 0x10000>;
		xlnx,s-axi-ctrl-addr-width = <0x7>;
		xlnx,pixels-per-clock = <4>;
		xlnx,samples-per-clock = <4>;
		xlnx,max-nr-planes = <2>;
		xlnx,has-bgr8 = <1>;
		xlnx,has-rgb8 = <1>;
		xlnx,has-y-uv8-420 = <0>;
		xlnx,has-yuyv8 = <1>;
		xlnx,has-y-u-v8 = <0>;
		interrupt-names = "interrupt";
		compatible = "xlnx,v-frmbuf-wr-3.0" , "xlnx,axi-frmbuf-wr-v2.2";
		xlnx,max-width = <3840>;
		xlnx,has-rgb16 = <0>;
		xlnx,vid-formats = "rgb888" , "bgr888" , "xbgr8888" , "xrgb8888" , "uyvy" , "y8" , "vuy888" , "xvuy8888" , "yuyv" , "nv16";
		xlnx,has-bgrx8 = <1>;
		xlnx,has-rgbx8 = <1>;
		xlnx,has-rgbx10 = <0>;
		interrupt-parent = <&axi_intc_0>;
		xlnx,aximm-num-outstanding = <4>;
		xlnx,has-uyvy8 = <1>;
		xlnx,use-uram = <0>;
		xlnx,has-rgbx12 = <0>;
		xlnx,aximm-burst-length = <16>;
		xlnx,aximm-addr-width = <64>;
		xlnx,video-width = <8>;
		xlnx,max-cols = <3840>;
		xlnx,has-yuv8 = <1>;
		xlnx,has-y-uv10-420 = <0>;
		xlnx,has-yuva8 = <0>;
		xlnx,has-y-uv12-420 = <0>;
		xlnx,name = "vcap_pipe1_v_frmbuf_wr_3";
		interrupts = < 7 2 >;
		xlnx,has-y10 = <0>;
		xlnx,has-y-uv16-420 = <0>;
		xlnx,has-y12 = <0>;
		xlnx,has-alpha = <0>;
		xlnx,has-y-u-v10 = <0>;
		clocks = <&misc_clk_2>;
		xlnx,has-y16 = <0>;
		xlnx,dma-align = <32>;
		xlnx,has-y-u-v12 = <0>;
		xlnx,edk-iptype = "PERIPHERAL";
		xlnx,has-interlaced = <0>;
		xlnx,has-yuv16 = <0>;
		xlnx,has-yuvx8 = <1>;
		xlnx,is-tile-format = <0>;
		xlnx,dma-addr-width = <64>;
		clock-names = "ap_clk";
		xlnx,s-axi-ctrl-data-width = <0x20>;
		xlnx,has-y8 = <1>;
		xlnx,has-y-uv10 = <0>;
		xlnx,has-y-uv12 = <0>;
		xlnx,max-rows = <2160>;
		xlnx,has-yuvx10 = <0>;
		#dma-cells = <1>;
		xlnx,has-yuvx12 = <0>;
		xlnx,has-y-uv16 = <0>;
		xlnx,max-data-width = <8>;
		xlnx,has-y-u-v8-420 = <0>;
		xlnx,num-video-components = <3>;
		xlnx,aximm-data-width = <256>;
	};
	vcap_pipe2_mipi_csi2_rx_subsyst_0: mipi_csi2_rx_subsystem@b0004000 {
		xlnx,data-lane2-byte = "All_Byte";
		xlnx,dpy-en-reg-if = <1>;
		xlnx,cmn-vc = <4>;
		xlnx,dphy-lanes = <4>;
		xlnx,ip-name = "mipi_csi2_rx_subsystem";
		reg = <0x0 0xb0004000 0x0 0x2000>;
		xlnx,vfb-tu-width = <1>;
		xlnx,ppc = <4>;
		xlnx,csi-buf-depth = <2048>;
		xlnx,exdes-fmc = "LI-IMX274MIPI-FMC , V1.0 , Single , Sensor";
		xlnx,supportlevel = <1>;
		xlnx,clk-lane-io-loc-name = "None";
		xlnx,max-lanes = <4>;
		xlnx,is-versal;
		xlnx,cmn-inc-iic = <0>;
		xlnx,clk-lane-io-loc = "None";
		xlnx,esc-timeout = <25600>;
		interrupt-names = "csirxss_csi_irq";
		xlnx,cmn-inc-vfb;
		xlnx,axis-tuser-width = <96>;
		compatible = "xlnx,mipi-csi2-rx-subsystem-6.0" , "xlnx,mipi-csi2-rx-subsystem-5.0";
		xlnx,en-active-lanes;
		xlnx,idly-tap = <1>;
		dphy-present = <0>;
		xlnx,cmn-num-pixels = <4>;
		xlnx,cmn-proj-family = <0>;
		xlnx,csi2rx-dbg = <0>;
		xlnx,fifo-rd-en-control;
		xlnx,vfb;
		interrupt-parent = <&axi_intc_0>;
		xlnx,data-lane1-io-loc-name = "None";
		xlnx,hs-timeout = <65541>;
		xlnx,data-lane3-io-loc-name = "None";
		xlnx,ext-mmcm = <0>;
		xlnx,data-lane1-byte = "All_Byte";
		xlnx,master-riu;
		xlnx,cal-mode = "NONE";
		rxphy-connected = <&vcap_pipe2_mipi_csi2_rx_subsyst_0_phy>;
		xlnx,mipi-rx-phy-mode = <1>;
		xlnx,data-lane0-io-position = <2>;
		xlnx,exdes-board = "VEK280";
		xlnx,data-lane2-io-position = <6>;
		xlnx,vc = <4>;
		xlnx,en-vcx = <0>;
		xlnx,name = "vcap_pipe2_mipi_csi2_rx_subsyst_0";
		xlnx,csi-emb-non-img = <0>;
		interrupts = < 8 2 >;
		xlnx,dphyrx-board-interface = "Custom";
		xlnx,data-lane3-io-loc = "None";
		xlnx,clock-mask = <39>;
		xlnx,hs-settle-ns = <25>;
		xlnx,en-cnts-byte-clk;
		clocks = <&misc_clk_1>, <&misc_clk_0>, <&misc_clk_2>;
		xlnx,data-lane2-io-loc = "None";
		xlnx,mipi-slv-int = <0>;
		xlnx,is-ksb;
		xlnx,cmn-fifo-rd-en-cntrl;
		xlnx,data-lane3-byte = "All_Byte";
		xlnx,stretch-line-rate = <4500>;
		xlnx,phy-mode = "DPHY";
		xlnx,axis-tdest-width = <4>;
		xlnx,en-csi-v2 = <0>;
		xlnx,edk-iptype = "PERIPHERAL";
		xlnx,init = <100000>;
		xlnx,cmn-pxl-format = <0x18>;
		xlnx,int-qor-check = <0>;
		clock-names = "dphy_clk_200M" , "lite_aclk" , "video_aclk";
		xlnx,data-lane1-io-loc = "None";
		xlnx,data-lane0-byte = "All_Byte";
		xlnx,ooc-vid-clk = <0x65b710>;
		csirx-present = <1>;
		xlnx,yuv420-buf-dpth = <128>;
		xlnx,hp-io-bank-selection = <64>;
		xlnx,idly-group-name = "mipi_csi2rx_idly_group";
		xlnx,lprx-disable-extport = <0>;
		csirx-connected = <&vcap_pipe2_mipi_csi2_rx_subsyst_0_rx>;
		xlnx,highaddr = <0xb0005fff>;
		xlnx,cmn-num-lanes = <4>;
		xlnx,exdes-config = "MIPI_Video_Pipe_Camera_to_Display";
		xlnx,exdesboard-version = <2>;
		xlnx,dphy-preset = "CSI2RX_XLNX";
		xlnx,data-lane0-io-loc-name = "None";
		xlnx,csi-pxl-format = <0x18>;
		xlnx,clk-lane-io-position = <0>;
		xlnx,data-lane2-io-loc-name = "None";
		xlnx,data-lane0-io-loc = "None";
		xlnx,inc-phy;
		xlnx,hs-line-rate = <800>;
		rxphy-present = <1>;
		xlnx,dpy-line-rate = <2500>;
		xlnx,csi-en-crc = <1>;
		xlnx,axis-tdata-width = <32>;
		xlnx,csi-controller-reg-if;
		xlnx,data-lane1-io-position = <4>;
		xlnx,dphy-mode = "SLAVE";
		xlnx,data-lane3-io-position = <8>;
		mipi_csi_portsvcap_pipe2_mipi_csi2_rx_subsyst_0: ports {
			#address-cells = <1>;
			#size-cells = <0>;
			mipi_csi_port1vcap_pipe2_mipi_csi2_rx_subsyst_0: port@1 {
				xlnx,video-width = <8>;
				reg = <1>;
				xlnx,video-format = <12>;
				xlnx,cfa-pattern = "rggb";
				mipi_csirx_outvcap_pipe2_mipi_csi2_rx_subsyst_0: endpoint {
					remote-endpoint = <&vcap_pipe2_mipi_csi2_rx_subsyst_0vcap_pipe2_mipi_csi2_rx_subsyst_0>;
				};
			};
			mipi_csi_port0vcap_pipe2_mipi_csi2_rx_subsyst_0: port@0 {
				xlnx,video-width = <8>;
				reg = <0>;
				xlnx,video-format = <12>;
				xlnx,cfa-pattern = "rggb";
				mipi_csi_invcap_pipe2_mipi_csi2_rx_subsyst_0: endpoint {
					data-lanes = < 1 2 3 4 >;
				};
			};
		};
	};
	vcap_pipe2_v_frmbuf_wr_0: v_frmbuf_wr@b00b0000 {
		xlnx,has-y-uv8 = <1>;
		reset-gpios = <&axi_gpio_rst 11 1>;
		xlnx,max-height = <2160>;
		xlnx,has-bgra8 = <0>;
		xlnx,has-rgba8 = <0>;
		xlnx,ip-name = "v_frmbuf_wr";
		reg = <0x0 0xb00b0000 0x0 0x10000>;
		xlnx,s-axi-ctrl-addr-width = <0x7>;
		xlnx,pixels-per-clock = <4>;
		xlnx,samples-per-clock = <4>;
		xlnx,max-nr-planes = <2>;
		xlnx,has-bgr8 = <1>;
		xlnx,has-rgb8 = <1>;
		xlnx,has-y-uv8-420 = <0>;
		xlnx,has-yuyv8 = <1>;
		xlnx,has-y-u-v8 = <0>;
		interrupt-names = "interrupt";
		compatible = "xlnx,v-frmbuf-wr-3.0" , "xlnx,axi-frmbuf-wr-v2.2";
		xlnx,max-width = <3840>;
		xlnx,has-rgb16 = <0>;
		xlnx,vid-formats = "rgb888" , "bgr888" , "xbgr8888" , "xrgb8888" , "uyvy" , "y8" , "vuy888" , "xvuy8888" , "yuyv" , "nv16";
		xlnx,has-bgrx8 = <1>;
		xlnx,has-rgbx8 = <1>;
		xlnx,has-rgbx10 = <0>;
		interrupt-parent = <&axi_intc_0>;
		xlnx,aximm-num-outstanding = <4>;
		xlnx,has-uyvy8 = <1>;
		xlnx,use-uram = <0>;
		xlnx,has-rgbx12 = <0>;
		xlnx,aximm-burst-length = <16>;
		xlnx,aximm-addr-width = <64>;
		xlnx,video-width = <8>;
		xlnx,max-cols = <3840>;
		xlnx,has-yuv8 = <1>;
		xlnx,has-y-uv10-420 = <0>;
		xlnx,has-yuva8 = <0>;
		xlnx,has-y-uv12-420 = <0>;
		xlnx,name = "vcap_pipe2_v_frmbuf_wr_0";
		interrupts = < 9 2 >;
		xlnx,has-y10 = <0>;
		xlnx,has-y-uv16-420 = <0>;
		xlnx,has-y12 = <0>;
		xlnx,has-alpha = <0>;
		xlnx,has-y-u-v10 = <0>;
		clocks = <&misc_clk_2>;
		xlnx,has-y16 = <0>;
		xlnx,dma-align = <32>;
		xlnx,has-y-u-v12 = <0>;
		xlnx,edk-iptype = "PERIPHERAL";
		xlnx,has-interlaced = <0>;
		xlnx,has-yuv16 = <0>;
		xlnx,has-yuvx8 = <1>;
		xlnx,is-tile-format = <0>;
		xlnx,dma-addr-width = <64>;
		clock-names = "ap_clk";
		xlnx,s-axi-ctrl-data-width = <0x20>;
		xlnx,has-y8 = <1>;
		xlnx,has-y-uv10 = <0>;
		xlnx,has-y-uv12 = <0>;
		xlnx,max-rows = <2160>;
		xlnx,has-yuvx10 = <0>;
		#dma-cells = <1>;
		xlnx,has-yuvx12 = <0>;
		xlnx,has-y-uv16 = <0>;
		xlnx,max-data-width = <8>;
		xlnx,has-y-u-v8-420 = <0>;
		xlnx,num-video-components = <3>;
		xlnx,aximm-data-width = <256>;
	};
	vcap_pipe2_v_frmbuf_wr_1: v_frmbuf_wr@b00c0000 {
		xlnx,has-y-uv8 = <1>;
		reset-gpios = <&axi_gpio_rst 12 1>;
		xlnx,max-height = <2160>;
		xlnx,has-bgra8 = <0>;
		xlnx,has-rgba8 = <0>;
		xlnx,ip-name = "v_frmbuf_wr";
		reg = <0x0 0xb00c0000 0x0 0x10000>;
		xlnx,s-axi-ctrl-addr-width = <0x7>;
		xlnx,pixels-per-clock = <4>;
		xlnx,samples-per-clock = <4>;
		xlnx,max-nr-planes = <2>;
		xlnx,has-bgr8 = <1>;
		xlnx,has-rgb8 = <1>;
		xlnx,has-y-uv8-420 = <0>;
		xlnx,has-yuyv8 = <1>;
		xlnx,has-y-u-v8 = <0>;
		interrupt-names = "interrupt";
		compatible = "xlnx,v-frmbuf-wr-3.0" , "xlnx,axi-frmbuf-wr-v2.2";
		xlnx,max-width = <3840>;
		xlnx,has-rgb16 = <0>;
		xlnx,vid-formats = "rgb888" , "bgr888" , "xbgr8888" , "xrgb8888" , "uyvy" , "y8" , "vuy888" , "xvuy8888" , "yuyv" , "nv16";
		xlnx,has-bgrx8 = <1>;
		xlnx,has-rgbx8 = <1>;
		xlnx,has-rgbx10 = <0>;
		interrupt-parent = <&axi_intc_0>;
		xlnx,aximm-num-outstanding = <4>;
		xlnx,has-uyvy8 = <1>;
		xlnx,use-uram = <0>;
		xlnx,has-rgbx12 = <0>;
		xlnx,aximm-burst-length = <16>;
		xlnx,aximm-addr-width = <64>;
		xlnx,video-width = <8>;
		xlnx,max-cols = <3840>;
		xlnx,has-yuv8 = <1>;
		xlnx,has-y-uv10-420 = <0>;
		xlnx,has-yuva8 = <0>;
		xlnx,has-y-uv12-420 = <0>;
		xlnx,name = "vcap_pipe2_v_frmbuf_wr_1";
		interrupts = < 10 2 >;
		xlnx,has-y10 = <0>;
		xlnx,has-y-uv16-420 = <0>;
		xlnx,has-y12 = <0>;
		xlnx,has-alpha = <0>;
		xlnx,has-y-u-v10 = <0>;
		clocks = <&misc_clk_2>;
		xlnx,has-y16 = <0>;
		xlnx,dma-align = <32>;
		xlnx,has-y-u-v12 = <0>;
		xlnx,edk-iptype = "PERIPHERAL";
		xlnx,has-interlaced = <0>;
		xlnx,has-yuv16 = <0>;
		xlnx,has-yuvx8 = <1>;
		xlnx,is-tile-format = <0>;
		xlnx,dma-addr-width = <64>;
		clock-names = "ap_clk";
		xlnx,s-axi-ctrl-data-width = <0x20>;
		xlnx,has-y8 = <1>;
		xlnx,has-y-uv10 = <0>;
		xlnx,has-y-uv12 = <0>;
		xlnx,max-rows = <2160>;
		xlnx,has-yuvx10 = <0>;
		#dma-cells = <1>;
		xlnx,has-yuvx12 = <0>;
		xlnx,has-y-uv16 = <0>;
		xlnx,max-data-width = <8>;
		xlnx,has-y-u-v8-420 = <0>;
		xlnx,num-video-components = <3>;
		xlnx,aximm-data-width = <256>;
	};
	vcap_pipe2_v_frmbuf_wr_2: v_frmbuf_wr@b00d0000 {
		xlnx,has-y-uv8 = <1>;
		reset-gpios = <&axi_gpio_rst 13 1>;
		xlnx,max-height = <2160>;
		xlnx,has-bgra8 = <0>;
		xlnx,has-rgba8 = <0>;
		xlnx,ip-name = "v_frmbuf_wr";
		reg = <0x0 0xb00d0000 0x0 0x10000>;
		xlnx,s-axi-ctrl-addr-width = <0x7>;
		xlnx,pixels-per-clock = <4>;
		xlnx,samples-per-clock = <4>;
		xlnx,max-nr-planes = <2>;
		xlnx,has-bgr8 = <1>;
		xlnx,has-rgb8 = <1>;
		xlnx,has-y-uv8-420 = <0>;
		xlnx,has-yuyv8 = <1>;
		xlnx,has-y-u-v8 = <0>;
		interrupt-names = "interrupt";
		compatible = "xlnx,v-frmbuf-wr-3.0" , "xlnx,axi-frmbuf-wr-v2.2";
		xlnx,max-width = <3840>;
		xlnx,has-rgb16 = <0>;
		xlnx,vid-formats = "rgb888" , "bgr888" , "xbgr8888" , "xrgb8888" , "uyvy" , "y8" , "vuy888" , "xvuy8888" , "yuyv" , "nv16";
		xlnx,has-bgrx8 = <1>;
		xlnx,has-rgbx8 = <1>;
		xlnx,has-rgbx10 = <0>;
		interrupt-parent = <&axi_intc_0>;
		xlnx,aximm-num-outstanding = <4>;
		xlnx,has-uyvy8 = <1>;
		xlnx,use-uram = <0>;
		xlnx,has-rgbx12 = <0>;
		xlnx,aximm-burst-length = <16>;
		xlnx,aximm-addr-width = <64>;
		xlnx,video-width = <8>;
		xlnx,max-cols = <3840>;
		xlnx,has-yuv8 = <1>;
		xlnx,has-y-uv10-420 = <0>;
		xlnx,has-yuva8 = <0>;
		xlnx,has-y-uv12-420 = <0>;
		xlnx,name = "vcap_pipe2_v_frmbuf_wr_2";
		interrupts = < 11 2 >;
		xlnx,has-y10 = <0>;
		xlnx,has-y-uv16-420 = <0>;
		xlnx,has-y12 = <0>;
		xlnx,has-alpha = <0>;
		xlnx,has-y-u-v10 = <0>;
		clocks = <&misc_clk_2>;
		xlnx,has-y16 = <0>;
		xlnx,dma-align = <32>;
		xlnx,has-y-u-v12 = <0>;
		xlnx,edk-iptype = "PERIPHERAL";
		xlnx,has-interlaced = <0>;
		xlnx,has-yuv16 = <0>;
		xlnx,has-yuvx8 = <1>;
		xlnx,is-tile-format = <0>;
		xlnx,dma-addr-width = <64>;
		clock-names = "ap_clk";
		xlnx,s-axi-ctrl-data-width = <0x20>;
		xlnx,has-y8 = <1>;
		xlnx,has-y-uv10 = <0>;
		xlnx,has-y-uv12 = <0>;
		xlnx,max-rows = <2160>;
		xlnx,has-yuvx10 = <0>;
		#dma-cells = <1>;
		xlnx,has-yuvx12 = <0>;
		xlnx,has-y-uv16 = <0>;
		xlnx,max-data-width = <8>;
		xlnx,has-y-u-v8-420 = <0>;
		xlnx,num-video-components = <3>;
		xlnx,aximm-data-width = <256>;
	};
	vcap_pipe2_v_frmbuf_wr_3: v_frmbuf_wr@b00e0000 {
		xlnx,has-y-uv8 = <1>;
		reset-gpios = <&axi_gpio_rst 14 1>;
		xlnx,max-height = <2160>;
		xlnx,has-bgra8 = <0>;
		xlnx,has-rgba8 = <0>;
		xlnx,ip-name = "v_frmbuf_wr";
		reg = <0x0 0xb00e0000 0x0 0x10000>;
		xlnx,s-axi-ctrl-addr-width = <0x7>;
		xlnx,pixels-per-clock = <4>;
		xlnx,samples-per-clock = <4>;
		xlnx,max-nr-planes = <2>;
		xlnx,has-bgr8 = <1>;
		xlnx,has-rgb8 = <1>;
		xlnx,has-y-uv8-420 = <0>;
		xlnx,has-yuyv8 = <1>;
		xlnx,has-y-u-v8 = <0>;
		interrupt-names = "interrupt";
		compatible = "xlnx,v-frmbuf-wr-3.0" , "xlnx,axi-frmbuf-wr-v2.2";
		xlnx,max-width = <3840>;
		xlnx,has-rgb16 = <0>;
		xlnx,vid-formats = "rgb888" , "bgr888" , "xbgr8888" , "xrgb8888" , "uyvy" , "y8" , "vuy888" , "xvuy8888" , "yuyv" , "nv16";
		xlnx,has-bgrx8 = <1>;
		xlnx,has-rgbx8 = <1>;
		xlnx,has-rgbx10 = <0>;
		interrupt-parent = <&axi_intc_0>;
		xlnx,aximm-num-outstanding = <4>;
		xlnx,has-uyvy8 = <1>;
		xlnx,use-uram = <0>;
		xlnx,has-rgbx12 = <0>;
		xlnx,aximm-burst-length = <16>;
		xlnx,aximm-addr-width = <64>;
		xlnx,video-width = <8>;
		xlnx,max-cols = <3840>;
		xlnx,has-yuv8 = <1>;
		xlnx,has-y-uv10-420 = <0>;
		xlnx,has-yuva8 = <0>;
		xlnx,has-y-uv12-420 = <0>;
		xlnx,name = "vcap_pipe2_v_frmbuf_wr_3";
		interrupts = < 12 2 >;
		xlnx,has-y10 = <0>;
		xlnx,has-y-uv16-420 = <0>;
		xlnx,has-y12 = <0>;
		xlnx,has-alpha = <0>;
		xlnx,has-y-u-v10 = <0>;
		clocks = <&misc_clk_2>;
		xlnx,has-y16 = <0>;
		xlnx,dma-align = <32>;
		xlnx,has-y-u-v12 = <0>;
		xlnx,edk-iptype = "PERIPHERAL";
		xlnx,has-interlaced = <0>;
		xlnx,has-yuv16 = <0>;
		xlnx,has-yuvx8 = <1>;
		xlnx,is-tile-format = <0>;
		xlnx,dma-addr-width = <64>;
		clock-names = "ap_clk";
		xlnx,s-axi-ctrl-data-width = <0x20>;
		xlnx,has-y8 = <1>;
		xlnx,has-y-uv10 = <0>;
		xlnx,has-y-uv12 = <0>;
		xlnx,max-rows = <2160>;
		xlnx,has-yuvx10 = <0>;
		#dma-cells = <1>;
		xlnx,has-yuvx12 = <0>;
		xlnx,has-y-uv16 = <0>;
		xlnx,max-data-width = <8>;
		xlnx,has-y-u-v8-420 = <0>;
		xlnx,num-video-components = <3>;
		xlnx,aximm-data-width = <256>;
	};
	vcap_pipe3_mipi_csi2_rx_subsyst_0: mipi_csi2_rx_subsystem@b0006000 {
		xlnx,data-lane2-byte = "All_Byte";
		xlnx,dpy-en-reg-if = <1>;
		xlnx,cmn-vc = <4>;
		xlnx,dphy-lanes = <4>;
		xlnx,ip-name = "mipi_csi2_rx_subsystem";
		reg = <0x0 0xb0006000 0x0 0x2000>;
		xlnx,vfb-tu-width = <1>;
		xlnx,ppc = <4>;
		xlnx,csi-buf-depth = <2048>;
		xlnx,exdes-fmc = "LI-IMX274MIPI-FMC , V1.0 , Single , Sensor";
		xlnx,supportlevel = <0>;
		xlnx,clk-lane-io-loc-name = "None";
		xlnx,max-lanes = <4>;
		xlnx,is-versal;
		xlnx,cmn-inc-iic = <0>;
		xlnx,clk-lane-io-loc = "None";
		xlnx,esc-timeout = <25600>;
		interrupt-names = "csirxss_csi_irq";
		xlnx,cmn-inc-vfb;
		xlnx,axis-tuser-width = <96>;
		compatible = "xlnx,mipi-csi2-rx-subsystem-6.0" , "xlnx,mipi-csi2-rx-subsystem-5.0";
		xlnx,en-active-lanes;
		xlnx,idly-tap = <1>;
		dphy-present = <0>;
		xlnx,cmn-num-pixels = <4>;
		xlnx,cmn-proj-family = <0>;
		xlnx,csi2rx-dbg = <0>;
		xlnx,fifo-rd-en-control;
		xlnx,vfb;
		interrupt-parent = <&axi_intc_0>;
		xlnx,data-lane1-io-loc-name = "None";
		xlnx,hs-timeout = <65541>;
		xlnx,data-lane3-io-loc-name = "None";
		xlnx,ext-mmcm = <0>;
		xlnx,data-lane1-byte = "All_Byte";
		xlnx,master-riu;
		xlnx,cal-mode = "NONE";
		rxphy-connected = <&vcap_pipe3_mipi_csi2_rx_subsyst_0_phy>;
		xlnx,mipi-rx-phy-mode = <1>;
		xlnx,data-lane0-io-position = <2>;
		xlnx,exdes-board = "VEK280";
		xlnx,data-lane2-io-position = <6>;
		xlnx,vc = <4>;
		xlnx,en-vcx = <0>;
		xlnx,name = "vcap_pipe3_mipi_csi2_rx_subsyst_0";
		xlnx,csi-emb-non-img = <0>;
		interrupts = < 13 2 >;
		xlnx,dphyrx-board-interface = "Custom";
		xlnx,data-lane3-io-loc = "None";
		xlnx,clock-mask = <39>;
		xlnx,hs-settle-ns = <25>;
		xlnx,en-cnts-byte-clk;
		clocks = <&misc_clk_3>, <&misc_clk_1>, <&misc_clk_0>, <&misc_clk_3>, <&misc_clk_2>;
		xlnx,data-lane2-io-loc = "None";
		xlnx,mipi-slv-int = <0>;
		xlnx,is-ksb;
		xlnx,cmn-fifo-rd-en-cntrl;
		xlnx,data-lane3-byte = "All_Byte";
		xlnx,stretch-line-rate = <4500>;
		xlnx,phy-mode = "DPHY";
		xlnx,axis-tdest-width = <4>;
		xlnx,en-csi-v2 = <0>;
		xlnx,edk-iptype = "PERIPHERAL";
		xlnx,init = <100000>;
		xlnx,cmn-pxl-format = <0x18>;
		xlnx,int-qor-check = <0>;
		clock-names = "cnts_rxwordclkhs_in" , "dphy_clk_200M" , "lite_aclk" , "shared_pll_clkoutphy_in" , "video_aclk";
		xlnx,data-lane1-io-loc = "None";
		xlnx,data-lane0-byte = "All_Byte";
		xlnx,ooc-vid-clk = <0x65b710>;
		csirx-present = <1>;
		xlnx,yuv420-buf-dpth = <128>;
		xlnx,hp-io-bank-selection = <64>;
		xlnx,idly-group-name = "mipi_csi2rx_idly_group";
		xlnx,lprx-disable-extport = <0>;
		csirx-connected = <&vcap_pipe3_mipi_csi2_rx_subsyst_0_rx>;
		xlnx,highaddr = <0xb0007fff>;
		xlnx,cmn-num-lanes = <4>;
		xlnx,exdes-config = "MIPI_Video_Pipe_Camera_to_Display";
		xlnx,exdesboard-version = <2>;
		xlnx,dphy-preset = "CSI2RX_XLNX";
		xlnx,data-lane0-io-loc-name = "None";
		xlnx,csi-pxl-format = <0x18>;
		xlnx,clk-lane-io-position = <0>;
		xlnx,data-lane2-io-loc-name = "None";
		xlnx,data-lane0-io-loc = "None";
		xlnx,inc-phy;
		xlnx,hs-line-rate = <800>;
		rxphy-present = <1>;
		xlnx,dpy-line-rate = <2500>;
		xlnx,csi-en-crc = <1>;
		xlnx,axis-tdata-width = <32>;
		xlnx,csi-controller-reg-if;
		xlnx,data-lane1-io-position = <4>;
		xlnx,dphy-mode = "SLAVE";
		xlnx,data-lane3-io-position = <8>;
		mipi_csi_portsvcap_pipe3_mipi_csi2_rx_subsyst_0: ports {
			#address-cells = <1>;
			#size-cells = <0>;
			mipi_csi_port1vcap_pipe3_mipi_csi2_rx_subsyst_0: port@1 {
				xlnx,video-width = <8>;
				reg = <1>;
				xlnx,video-format = <12>;
				xlnx,cfa-pattern = "rggb";
				mipi_csirx_outvcap_pipe3_mipi_csi2_rx_subsyst_0: endpoint {
					remote-endpoint = <&vcap_pipe3_mipi_csi2_rx_subsyst_0vcap_pipe3_mipi_csi2_rx_subsyst_0>;
				};
			};
			mipi_csi_port0vcap_pipe3_mipi_csi2_rx_subsyst_0: port@0 {
				xlnx,video-width = <8>;
				reg = <0>;
				xlnx,video-format = <12>;
				xlnx,cfa-pattern = "rggb";
				mipi_csi_invcap_pipe3_mipi_csi2_rx_subsyst_0: endpoint {
					data-lanes = < 1 2 3 4 >;
				};
			};
		};
	};
	vcap_pipe3_v_frmbuf_wr_0: v_frmbuf_wr@b00f0000 {
		xlnx,has-y-uv8 = <1>;
		reset-gpios = <&axi_gpio_rst 16 1>;
		xlnx,max-height = <2160>;
		xlnx,has-bgra8 = <0>;
		xlnx,has-rgba8 = <0>;
		xlnx,ip-name = "v_frmbuf_wr";
		reg = <0x0 0xb00f0000 0x0 0x10000>;
		xlnx,s-axi-ctrl-addr-width = <0x7>;
		xlnx,pixels-per-clock = <4>;
		xlnx,samples-per-clock = <4>;
		xlnx,max-nr-planes = <2>;
		xlnx,has-bgr8 = <1>;
		xlnx,has-rgb8 = <1>;
		xlnx,has-y-uv8-420 = <0>;
		xlnx,has-yuyv8 = <1>;
		xlnx,has-y-u-v8 = <0>;
		interrupt-names = "interrupt";
		compatible = "xlnx,v-frmbuf-wr-3.0" , "xlnx,axi-frmbuf-wr-v2.2";
		xlnx,max-width = <3840>;
		xlnx,has-rgb16 = <0>;
		xlnx,vid-formats = "rgb888" , "bgr888" , "xbgr8888" , "xrgb8888" , "uyvy" , "y8" , "vuy888" , "xvuy8888" , "yuyv" , "nv16";
		xlnx,has-bgrx8 = <1>;
		xlnx,has-rgbx8 = <1>;
		xlnx,has-rgbx10 = <0>;
		interrupt-parent = <&axi_intc_0>;
		xlnx,aximm-num-outstanding = <4>;
		xlnx,has-uyvy8 = <1>;
		xlnx,use-uram = <0>;
		xlnx,has-rgbx12 = <0>;
		xlnx,aximm-burst-length = <16>;
		xlnx,aximm-addr-width = <64>;
		xlnx,video-width = <8>;
		xlnx,max-cols = <3840>;
		xlnx,has-yuv8 = <1>;
		xlnx,has-y-uv10-420 = <0>;
		xlnx,has-yuva8 = <0>;
		xlnx,has-y-uv12-420 = <0>;
		xlnx,name = "vcap_pipe3_v_frmbuf_wr_0";
		interrupts = < 14 2 >;
		xlnx,has-y10 = <0>;
		xlnx,has-y-uv16-420 = <0>;
		xlnx,has-y12 = <0>;
		xlnx,has-alpha = <0>;
		xlnx,has-y-u-v10 = <0>;
		clocks = <&misc_clk_2>;
		xlnx,has-y16 = <0>;
		xlnx,dma-align = <32>;
		xlnx,has-y-u-v12 = <0>;
		xlnx,edk-iptype = "PERIPHERAL";
		xlnx,has-interlaced = <0>;
		xlnx,has-yuv16 = <0>;
		xlnx,has-yuvx8 = <1>;
		xlnx,is-tile-format = <0>;
		xlnx,dma-addr-width = <64>;
		clock-names = "ap_clk";
		xlnx,s-axi-ctrl-data-width = <0x20>;
		xlnx,has-y8 = <1>;
		xlnx,has-y-uv10 = <0>;
		xlnx,has-y-uv12 = <0>;
		xlnx,max-rows = <2160>;
		xlnx,has-yuvx10 = <0>;
		#dma-cells = <1>;
		xlnx,has-yuvx12 = <0>;
		xlnx,has-y-uv16 = <0>;
		xlnx,max-data-width = <8>;
		xlnx,has-y-u-v8-420 = <0>;
		xlnx,num-video-components = <3>;
		xlnx,aximm-data-width = <256>;
	};
	vcap_pipe3_v_frmbuf_wr_1: v_frmbuf_wr@b0100000 {
		xlnx,has-y-uv8 = <1>;
		reset-gpios = <&axi_gpio_rst 17 1>;
		xlnx,max-height = <2160>;
		xlnx,has-bgra8 = <0>;
		xlnx,has-rgba8 = <0>;
		xlnx,ip-name = "v_frmbuf_wr";
		reg = <0x0 0xb0100000 0x0 0x10000>;
		xlnx,s-axi-ctrl-addr-width = <0x7>;
		xlnx,pixels-per-clock = <4>;
		xlnx,samples-per-clock = <4>;
		xlnx,max-nr-planes = <2>;
		xlnx,has-bgr8 = <1>;
		xlnx,has-rgb8 = <1>;
		xlnx,has-y-uv8-420 = <0>;
		xlnx,has-yuyv8 = <1>;
		xlnx,has-y-u-v8 = <0>;
		interrupt-names = "interrupt";
		compatible = "xlnx,v-frmbuf-wr-3.0" , "xlnx,axi-frmbuf-wr-v2.2";
		xlnx,max-width = <3840>;
		xlnx,has-rgb16 = <0>;
		xlnx,vid-formats = "rgb888" , "bgr888" , "xbgr8888" , "xrgb8888" , "uyvy" , "y8" , "vuy888" , "xvuy8888" , "yuyv" , "nv16";
		xlnx,has-bgrx8 = <1>;
		xlnx,has-rgbx8 = <1>;
		xlnx,has-rgbx10 = <0>;
		interrupt-parent = <&axi_intc_0>;
		xlnx,aximm-num-outstanding = <4>;
		xlnx,has-uyvy8 = <1>;
		xlnx,use-uram = <0>;
		xlnx,has-rgbx12 = <0>;
		xlnx,aximm-burst-length = <16>;
		xlnx,aximm-addr-width = <64>;
		xlnx,video-width = <8>;
		xlnx,max-cols = <3840>;
		xlnx,has-yuv8 = <1>;
		xlnx,has-y-uv10-420 = <0>;
		xlnx,has-yuva8 = <0>;
		xlnx,has-y-uv12-420 = <0>;
		xlnx,name = "vcap_pipe3_v_frmbuf_wr_1";
		interrupts = < 15 2 >;
		xlnx,has-y10 = <0>;
		xlnx,has-y-uv16-420 = <0>;
		xlnx,has-y12 = <0>;
		xlnx,has-alpha = <0>;
		xlnx,has-y-u-v10 = <0>;
		clocks = <&misc_clk_2>;
		xlnx,has-y16 = <0>;
		xlnx,dma-align = <32>;
		xlnx,has-y-u-v12 = <0>;
		xlnx,edk-iptype = "PERIPHERAL";
		xlnx,has-interlaced = <0>;
		xlnx,has-yuv16 = <0>;
		xlnx,has-yuvx8 = <1>;
		xlnx,is-tile-format = <0>;
		xlnx,dma-addr-width = <64>;
		clock-names = "ap_clk";
		xlnx,s-axi-ctrl-data-width = <0x20>;
		xlnx,has-y8 = <1>;
		xlnx,has-y-uv10 = <0>;
		xlnx,has-y-uv12 = <0>;
		xlnx,max-rows = <2160>;
		xlnx,has-yuvx10 = <0>;
		#dma-cells = <1>;
		xlnx,has-yuvx12 = <0>;
		xlnx,has-y-uv16 = <0>;
		xlnx,max-data-width = <8>;
		xlnx,has-y-u-v8-420 = <0>;
		xlnx,num-video-components = <3>;
		xlnx,aximm-data-width = <256>;
	};
	vcap_pipe3_v_frmbuf_wr_2: v_frmbuf_wr@b0110000 {
		xlnx,has-y-uv8 = <1>;
		reset-gpios = <&axi_gpio_rst 18 1>;
		xlnx,max-height = <2160>;
		xlnx,has-bgra8 = <0>;
		xlnx,has-rgba8 = <0>;
		xlnx,ip-name = "v_frmbuf_wr";
		reg = <0x0 0xb0110000 0x0 0x10000>;
		xlnx,s-axi-ctrl-addr-width = <0x7>;
		xlnx,pixels-per-clock = <4>;
		xlnx,samples-per-clock = <4>;
		xlnx,max-nr-planes = <2>;
		xlnx,has-bgr8 = <1>;
		xlnx,has-rgb8 = <1>;
		xlnx,has-y-uv8-420 = <0>;
		xlnx,has-yuyv8 = <1>;
		xlnx,has-y-u-v8 = <0>;
		interrupt-names = "interrupt";
		compatible = "xlnx,v-frmbuf-wr-3.0" , "xlnx,axi-frmbuf-wr-v2.2";
		xlnx,max-width = <3840>;
		xlnx,has-rgb16 = <0>;
		xlnx,vid-formats = "rgb888" , "bgr888" , "xbgr8888" , "xrgb8888" , "uyvy" , "y8" , "vuy888" , "xvuy8888" , "yuyv" , "nv16";
		xlnx,has-bgrx8 = <1>;
		xlnx,has-rgbx8 = <1>;
		xlnx,has-rgbx10 = <0>;
		interrupt-parent = <&axi_intc_0>;
		xlnx,aximm-num-outstanding = <4>;
		xlnx,has-uyvy8 = <1>;
		xlnx,use-uram = <0>;
		xlnx,has-rgbx12 = <0>;
		xlnx,aximm-burst-length = <16>;
		xlnx,aximm-addr-width = <64>;
		xlnx,video-width = <8>;
		xlnx,max-cols = <3840>;
		xlnx,has-yuv8 = <1>;
		xlnx,has-y-uv10-420 = <0>;
		xlnx,has-yuva8 = <0>;
		xlnx,has-y-uv12-420 = <0>;
		xlnx,name = "vcap_pipe3_v_frmbuf_wr_2";
		interrupts = < 16 2 >;
		xlnx,has-y10 = <0>;
		xlnx,has-y-uv16-420 = <0>;
		xlnx,has-y12 = <0>;
		xlnx,has-alpha = <0>;
		xlnx,has-y-u-v10 = <0>;
		clocks = <&misc_clk_2>;
		xlnx,has-y16 = <0>;
		xlnx,dma-align = <32>;
		xlnx,has-y-u-v12 = <0>;
		xlnx,edk-iptype = "PERIPHERAL";
		xlnx,has-interlaced = <0>;
		xlnx,has-yuv16 = <0>;
		xlnx,has-yuvx8 = <1>;
		xlnx,is-tile-format = <0>;
		xlnx,dma-addr-width = <64>;
		clock-names = "ap_clk";
		xlnx,s-axi-ctrl-data-width = <0x20>;
		xlnx,has-y8 = <1>;
		xlnx,has-y-uv10 = <0>;
		xlnx,has-y-uv12 = <0>;
		xlnx,max-rows = <2160>;
		xlnx,has-yuvx10 = <0>;
		#dma-cells = <1>;
		xlnx,has-yuvx12 = <0>;
		xlnx,has-y-uv16 = <0>;
		xlnx,max-data-width = <8>;
		xlnx,has-y-u-v8-420 = <0>;
		xlnx,num-video-components = <3>;
		xlnx,aximm-data-width = <256>;
	};
	vcap_pipe3_v_frmbuf_wr_3: v_frmbuf_wr@b0120000 {
		xlnx,has-y-uv8 = <1>;
		reset-gpios = <&axi_gpio_rst 19 1>;
		xlnx,max-height = <2160>;
		xlnx,has-bgra8 = <0>;
		xlnx,has-rgba8 = <0>;
		xlnx,ip-name = "v_frmbuf_wr";
		reg = <0x0 0xb0120000 0x0 0x10000>;
		xlnx,s-axi-ctrl-addr-width = <0x7>;
		xlnx,pixels-per-clock = <4>;
		xlnx,samples-per-clock = <4>;
		xlnx,max-nr-planes = <2>;
		xlnx,has-bgr8 = <1>;
		xlnx,has-rgb8 = <1>;
		xlnx,has-y-uv8-420 = <0>;
		xlnx,has-yuyv8 = <1>;
		xlnx,has-y-u-v8 = <0>;
		interrupt-names = "interrupt";
		compatible = "xlnx,v-frmbuf-wr-3.0" , "xlnx,axi-frmbuf-wr-v2.2";
		xlnx,max-width = <3840>;
		xlnx,has-rgb16 = <0>;
		xlnx,vid-formats = "rgb888" , "bgr888" , "xbgr8888" , "xrgb8888" , "uyvy" , "y8" , "vuy888" , "xvuy8888" , "yuyv" , "nv16";
		xlnx,has-bgrx8 = <1>;
		xlnx,has-rgbx8 = <1>;
		xlnx,has-rgbx10 = <0>;
		interrupt-parent = <&axi_intc_0>;
		xlnx,aximm-num-outstanding = <4>;
		xlnx,has-uyvy8 = <1>;
		xlnx,use-uram = <0>;
		xlnx,has-rgbx12 = <0>;
		xlnx,aximm-burst-length = <16>;
		xlnx,aximm-addr-width = <64>;
		xlnx,video-width = <8>;
		xlnx,max-cols = <3840>;
		xlnx,has-yuv8 = <1>;
		xlnx,has-y-uv10-420 = <0>;
		xlnx,has-yuva8 = <0>;
		xlnx,has-y-uv12-420 = <0>;
		xlnx,name = "vcap_pipe3_v_frmbuf_wr_3";
		interrupts = < 17 2 >;
		xlnx,has-y10 = <0>;
		xlnx,has-y-uv16-420 = <0>;
		xlnx,has-y12 = <0>;
		xlnx,has-alpha = <0>;
		xlnx,has-y-u-v10 = <0>;
		clocks = <&misc_clk_2>;
		xlnx,has-y16 = <0>;
		xlnx,dma-align = <32>;
		xlnx,has-y-u-v12 = <0>;
		xlnx,edk-iptype = "PERIPHERAL";
		xlnx,has-interlaced = <0>;
		xlnx,has-yuv16 = <0>;
		xlnx,has-yuvx8 = <1>;
		xlnx,is-tile-format = <0>;
		xlnx,dma-addr-width = <64>;
		clock-names = "ap_clk";
		xlnx,s-axi-ctrl-data-width = <0x20>;
		xlnx,has-y8 = <1>;
		xlnx,has-y-uv10 = <0>;
		xlnx,has-y-uv12 = <0>;
		xlnx,max-rows = <2160>;
		xlnx,has-yuvx10 = <0>;
		#dma-cells = <1>;
		xlnx,has-yuvx12 = <0>;
		xlnx,has-y-uv16 = <0>;
		xlnx,max-data-width = <8>;
		xlnx,has-y-u-v8-420 = <0>;
		xlnx,num-video-components = <3>;
		xlnx,aximm-data-width = <256>;
	};
	vcap_pipe1_mipi_csi2_rx_subsyst_0_phy: vcap_pipe1_mipi_csi2_rx_subsyst_0_phy@1000 {
		xlnx,en-csi-cnts-word-clk;
		xlnx,en-alp = <0>;
		xlnx,ip-name = "mipi_rx_phy";
		reg = <0x0 0xb0001000 0x0 0x1000>;
		xlnx,line-rate = <2500>;
		xlnx,max-symbols = <16>;
		xlnx,ppi-rxdwidth = <32>;
		xlnx,supportlevel;
		xlnx,alp-pause-wake-ulps = <156250>;
		xlnx,esc-timeout = <25600>;
		xlnx,data-width = <32>;
		xlnx,lib-fifo = <1>;
		xlnx,ddr-clk-period = <0xc3500>;
		xlnx,phy-lanes = <3>;
		compatible = "xlnx,mipi-rx-phy-1.0";
		xlnx,prbs-seed = <0000000000000001>;
		xlnx,en-preamble-seq = <0>;
		xlnx,hs-timeout = <65541>;
		xlnx,alp-pause-wake-stop = <15>;
		xlnx,ppi-v-width = <1>;
		xlnx,en-esc-mode = <0>;
		xlnx,wakeup = <200000>;
		xlnx,en-init-periodic-seq = <0>;
		xlnx,stb-width = <4>;
		xlnx,en-ulps-wakeup-cnt = <0>;
		xlnx,name = "vcap_pipe1_mipi_csi2_rx_subsyst_0_phy";
		xlnx,phy-preset = "None";
		xlnx,clock-mask = <39>;
		xlnx,addr-width = <8>;
		xlnx,is-hierarchy;
		clocks = <&misc_clk_1>, <&misc_clk_0>;
		xlnx,stable-clk-period = <200>;
		xlnx,phy-mode = <0>;
		xlnx,edk-iptype = "PERIPHERAL";
		xlnx,init-cntr-1 = <1024>;
		xlnx,en-alt-seq = <0>;
		xlnx,init-cntr-2 = <17>;
		clock-names = "core_clk" , "s_axi_aclk";
		xlnx,hs-settle = <16>;
		xlnx,esc-clk-period = <50>;
		xlnx,calib-en = <0>;
		xlnx,en-timeout-regs = <0>;
		xlnx,back2back-sync = <0>;
		xlnx,resp-width = <2>;
		xlnx,dbg-ports-on = <0>;
		xlnx,reg-on = <1>;
		xlnx,cts-en-phy-init = <0>;
	};
	vcap_pipe1_mipi_csi2_rx_subsyst_0_rx: vcap_pipe1_mipi_csi2_rx_subsyst_0_rx@0 {
		xlnx,ip-name = "mipi_csi2_rx_ctrl";
		reg = <0x0 0xb0000000 0x0 0x1000>;
		xlnx,ppi-sig-width = <1>;
		xlnx,cmn-inc-vfb;
		xlnx,axis-tuser-width = <128>;
		compatible = "xlnx,mipi-csi2-rx-ctrl-1.0";
		xlnx,cmn-num-pixels = <4>;
		xlnx,cmn-proj-family = <0>;
		xlnx,csi2rx-dbg = <0>;
		xlnx,csi-opt1-regs = <0>;
		xlnx,disable-lite = <0>;
		xlnx,ppi-sync-width = <1>;
		xlnx,csi-filter-userdatatype = <0>;
		xlnx,csi-offload-nonimage = <0>;
		xlnx,csi-vc-off-10 = <11>;
		xlnx,emb-dw = <192>;
		xlnx,csi-vc-off-11 = <12>;
		xlnx,csi-vc-off-12 = <13>;
		xlnx,csi-vc-off-13 = <14>;
		xlnx,csi-vc-off-14 = <15>;
		xlnx,ppi-mult = <3>;
		xlnx,name = "vcap_pipe1_mipi_csi2_rx_subsyst_0_rx";
		xlnx,en-vcx;
		xlnx,csi-vc-off-0 = <1>;
		xlnx,csi-vc-off-1 = <2>;
		xlnx,csi-vc-off-2 = <3>;
		xlnx,csi-vc-off-3 = <4>;
		xlnx,csi-vc-off-4 = <5>;
		xlnx,csi-lanes = <3>;
		xlnx,csi-vc-off-5 = <6>;
		xlnx,is-hierarchy;
		xlnx,axis-fifo-depth = <2048>;
		xlnx,csi-vc-off-6 = <7>;
		clocks = <&misc_clk_1>, <&misc_clk_3>, <&misc_clk_2>, <&misc_clk_0>, <&misc_clk_2>;
		xlnx,axis-fifo-dcnt-width = <11>;
		xlnx,mipi-slv-int = <0>;
		xlnx,csi-vc-off-7 = <8>;
		xlnx,csi-vc-off-8 = <9>;
		xlnx,axis-tdest-width = <11>;
		xlnx,phy-mode = "CPHY";
		xlnx,csi-vc-off-9 = <10>;
		xlnx,edk-iptype = "PERIPHERAL";
		xlnx,cmn-pxl-format = "YUV422_8bit";
		xlnx,csi-opt2-crc = <0>;
		clock-names = "core_clk" , "dl0_rxbyteclkhs" , "m_axis_aclk" , "s_axi_aclk" , "video_aclk";
		xlnx,yuv420-buf-dpth = <128>;
		xlnx,hp-io-bank-selection = <46>;
		xlnx,csi-opt3-fixedlanes = <1>;
		xlnx,csi-en-vc-support = <1>;
		xlnx,hs-line-rate = <2500>;
		xlnx,csi-fixed-vc = <0>;
		xlnx,csi-inv-shutdown = <1>;
		xlnx,axis-tdata-width = <64>;
		xlnx,header-data-width = <48>;
	};
	vcap_pipe2_mipi_csi2_rx_subsyst_0_phy: vcap_pipe2_mipi_csi2_rx_subsyst_0_phy@1000 {
		xlnx,en-csi-cnts-word-clk;
		xlnx,en-alp = <0>;
		xlnx,ip-name = "mipi_rx_phy";
		reg = <0x0 0xb0005000 0x0 0x1000>;
		xlnx,line-rate = <2500>;
		xlnx,max-symbols = <16>;
		xlnx,ppi-rxdwidth = <16>;
		xlnx,supportlevel;
		xlnx,alp-pause-wake-ulps = <50>;
		xlnx,esc-timeout = <25600>;
		xlnx,data-width = <32>;
		xlnx,lib-fifo = <1>;
		xlnx,ddr-clk-period = <0xc3500>;
		xlnx,phy-lanes = <4>;
		compatible = "xlnx,mipi-rx-phy-1.0";
		xlnx,prbs-seed = <0000000000000001>;
		xlnx,en-preamble-seq = <0>;
		xlnx,hs-timeout = <65541>;
		xlnx,alp-pause-wake-stop = <4>;
		xlnx,ppi-v-width = <1>;
		xlnx,en-esc-mode = <0>;
		xlnx,wakeup = <200000>;
		xlnx,en-init-periodic-seq = <0>;
		xlnx,stb-width = <4>;
		xlnx,en-ulps-wakeup-cnt = <0>;
		xlnx,name = "vcap_pipe2_mipi_csi2_rx_subsyst_0_phy";
		xlnx,phy-preset = "CSI2RX_XLNX";
		xlnx,clock-mask = <39>;
		xlnx,addr-width = <8>;
		xlnx,is-hierarchy;
		clocks = <&misc_clk_1>, <&misc_clk_0>;
		xlnx,stable-clk-period = <200>;
		xlnx,phy-mode = <1>;
		xlnx,edk-iptype = "PERIPHERAL";
		xlnx,init-cntr-1 = <1024>;
		xlnx,en-alt-seq = <0>;
		xlnx,init-cntr-2 = <20>;
		clock-names = "core_clk" , "s_axi_aclk";
		xlnx,hs-settle = <25>;
		xlnx,esc-clk-period = <50>;
		xlnx,calib-en = <1>;
		xlnx,en-timeout-regs = <0>;
		xlnx,back2back-sync = <0>;
		xlnx,resp-width = <2>;
		xlnx,dbg-ports-on = <0>;
		xlnx,reg-on = <1>;
		xlnx,cts-en-phy-init = <0>;
	};
	vcap_pipe2_mipi_csi2_rx_subsyst_0_rx: vcap_pipe2_mipi_csi2_rx_subsyst_0_rx@0 {
		xlnx,ip-name = "mipi_csi2_rx_ctrl";
		reg = <0x0 0xb0004000 0x0 0x1000>;
		xlnx,ppi-sig-width = <1>;
		xlnx,cmn-inc-vfb;
		xlnx,axis-tuser-width = <96>;
		compatible = "xlnx,mipi-csi2-rx-ctrl-1.0";
		xlnx,cmn-num-pixels = <4>;
		xlnx,cmn-proj-family = <0>;
		xlnx,csi2rx-dbg = <0>;
		xlnx,csi-opt1-regs = <0>;
		xlnx,disable-lite = <0>;
		xlnx,ppi-sync-width = <0>;
		xlnx,csi-filter-userdatatype = <0>;
		xlnx,csi-offload-nonimage = <0>;
		xlnx,csi-vc-off-10 = <11>;
		xlnx,emb-dw = <192>;
		xlnx,csi-vc-off-11 = <12>;
		xlnx,csi-vc-off-12 = <13>;
		xlnx,csi-vc-off-13 = <14>;
		xlnx,csi-vc-off-14 = <15>;
		xlnx,ppi-mult = <1>;
		xlnx,name = "vcap_pipe2_mipi_csi2_rx_subsyst_0_rx";
		xlnx,en-vcx;
		xlnx,csi-vc-off-0 = <1>;
		xlnx,csi-vc-off-1 = <2>;
		xlnx,csi-vc-off-2 = <3>;
		xlnx,csi-vc-off-3 = <4>;
		xlnx,csi-vc-off-4 = <5>;
		xlnx,csi-lanes = <4>;
		xlnx,csi-vc-off-5 = <6>;
		xlnx,is-hierarchy;
		xlnx,axis-fifo-depth = <2048>;
		xlnx,csi-vc-off-6 = <7>;
		clocks = <&misc_clk_1>, <&misc_clk_3>, <&misc_clk_2>, <&misc_clk_0>, <&misc_clk_2>;
		xlnx,axis-fifo-dcnt-width = <11>;
		xlnx,mipi-slv-int = <0>;
		xlnx,csi-vc-off-7 = <8>;
		xlnx,csi-vc-off-8 = <9>;
		xlnx,axis-tdest-width = <11>;
		xlnx,phy-mode = "DPHY";
		xlnx,csi-vc-off-9 = <10>;
		xlnx,edk-iptype = "PERIPHERAL";
		xlnx,cmn-pxl-format = "YUV422_8bit";
		xlnx,csi-opt2-crc = <0>;
		clock-names = "core_clk" , "dl0_rxbyteclkhs" , "m_axis_aclk" , "s_axi_aclk" , "video_aclk";
		xlnx,yuv420-buf-dpth = <128>;
		xlnx,hp-io-bank-selection = <46>;
		xlnx,csi-opt3-fixedlanes = <1>;
		xlnx,csi-en-vc-support = <1>;
		xlnx,hs-line-rate = <2500>;
		xlnx,csi-fixed-vc = <0>;
		xlnx,csi-inv-shutdown = <1>;
		xlnx,axis-tdata-width = <64>;
		xlnx,header-data-width = <32>;
	};
	vcap_pipe3_mipi_csi2_rx_subsyst_0_phy: vcap_pipe3_mipi_csi2_rx_subsyst_0_phy@1000 {
		xlnx,esc-clk-period = <50>;
		compatible = "xlnx,mipi-rx-phy-1.0";
		xlnx,calib-en = <1>;
		xlnx,prbs-seed = <0000000000000001>;
		xlnx,en-timeout-regs = <0>;
		xlnx,en-alp = <0>;
		xlnx,clock-mask = <39>;
		xlnx,en-preamble-seq = <0>;
		xlnx,back2back-sync = <0>;
		xlnx,resp-width = <2>;
		xlnx,hs-timeout = <65541>;
		xlnx,ip-name = "mipi_rx_phy";
		xlnx,is-hierarchy;
		reg = <0x0 0xb0007000 0x0 0x1000>;
		xlnx,addr-width = <8>;
		xlnx,alp-pause-wake-stop = <4>;
		clocks = <&misc_clk_3>, <&misc_clk_1>, <&misc_clk_0>;
		xlnx,ppi-v-width = <1>;
		xlnx,line-rate = <2500>;
		xlnx,stable-clk-period = <200>;
		xlnx,phy-mode = <1>;
		xlnx,edk-iptype = "PERIPHERAL";
		xlnx,ppi-rxdwidth = <16>;
		xlnx,max-symbols = <16>;
		xlnx,dbg-ports-on = <0>;
		xlnx,wakeup = <200000>;
		xlnx,en-esc-mode = <0>;
		xlnx,stb-width = <4>;
		xlnx,init-cntr-1 = <1024>;
		xlnx,en-init-periodic-seq = <0>;
		xlnx,alp-pause-wake-ulps = <50>;
		clock-names = "cnts_rxwordclkhs_in" , "core_clk" , "s_axi_aclk";
		xlnx,data-width = <32>;
		xlnx,init-cntr-2 = <20>;
		xlnx,esc-timeout = <25600>;
		xlnx,en-alt-seq = <0>;
		xlnx,reg-on = <1>;
		xlnx,lib-fifo = <1>;
		xlnx,en-ulps-wakeup-cnt = <0>;
		xlnx,phy-preset = "CSI2RX_XLNX";
		xlnx,phy-lanes = <4>;
		xlnx,hs-settle = <25>;
		xlnx,ddr-clk-period = <0xc3500>;
		xlnx,name = "vcap_pipe3_mipi_csi2_rx_subsyst_0_phy";
		xlnx,cts-en-phy-init = <0>;
	};
	vcap_pipe3_mipi_csi2_rx_subsyst_0_rx: vcap_pipe3_mipi_csi2_rx_subsyst_0_rx@0 {
		xlnx,ip-name = "mipi_csi2_rx_ctrl";
		reg = <0x0 0xb0006000 0x0 0x1000>;
		xlnx,ppi-sig-width = <1>;
		xlnx,cmn-inc-vfb;
		xlnx,axis-tuser-width = <96>;
		compatible = "xlnx,mipi-csi2-rx-ctrl-1.0";
		xlnx,cmn-num-pixels = <4>;
		xlnx,cmn-proj-family = <0>;
		xlnx,csi2rx-dbg = <0>;
		xlnx,csi-opt1-regs = <0>;
		xlnx,disable-lite = <0>;
		xlnx,ppi-sync-width = <0>;
		xlnx,csi-filter-userdatatype = <0>;
		xlnx,csi-offload-nonimage = <0>;
		xlnx,csi-vc-off-10 = <11>;
		xlnx,emb-dw = <192>;
		xlnx,csi-vc-off-11 = <12>;
		xlnx,csi-vc-off-12 = <13>;
		xlnx,csi-vc-off-13 = <14>;
		xlnx,csi-vc-off-14 = <15>;
		xlnx,ppi-mult = <1>;
		xlnx,name = "vcap_pipe3_mipi_csi2_rx_subsyst_0_rx";
		xlnx,en-vcx;
		xlnx,csi-vc-off-0 = <1>;
		xlnx,csi-vc-off-1 = <2>;
		xlnx,csi-vc-off-2 = <3>;
		xlnx,csi-vc-off-3 = <4>;
		xlnx,csi-vc-off-4 = <5>;
		xlnx,csi-lanes = <4>;
		xlnx,csi-vc-off-5 = <6>;
		xlnx,is-hierarchy;
		xlnx,axis-fifo-depth = <2048>;
		xlnx,csi-vc-off-6 = <7>;
		clocks = <&misc_clk_1>, <&misc_clk_4>, <&misc_clk_2>, <&misc_clk_0>, <&misc_clk_2>;
		xlnx,axis-fifo-dcnt-width = <11>;
		xlnx,mipi-slv-int = <0>;
		xlnx,csi-vc-off-7 = <8>;
		xlnx,csi-vc-off-8 = <9>;
		xlnx,axis-tdest-width = <11>;
		xlnx,phy-mode = "DPHY";
		xlnx,csi-vc-off-9 = <10>;
		xlnx,edk-iptype = "PERIPHERAL";
		xlnx,cmn-pxl-format = "YUV422_8bit";
		xlnx,csi-opt2-crc = <0>;
		clock-names = "core_clk" , "dl0_rxbyteclkhs" , "m_axis_aclk" , "s_axi_aclk" , "video_aclk";
		xlnx,yuv420-buf-dpth = <128>;
		xlnx,hp-io-bank-selection = <46>;
		xlnx,csi-opt3-fixedlanes = <1>;
		xlnx,csi-en-vc-support = <1>;
		xlnx,hs-line-rate = <2500>;
		xlnx,csi-fixed-vc = <0>;
		xlnx,csi-inv-shutdown = <1>;
		xlnx,axis-tdata-width = <64>;
		xlnx,header-data-width = <32>;
	};
	vcap_pipe1_axis_switch_0: axis_switch_vcap_pipe1_axis_switch_0@0 {
		compatible = "xlnx,axis-switch-1.1";
		xlnx,routing-mode = <0>;
		xlnx,num-si-slots = <1>;
		xlnx,num-mi-slots = <4>;
		axis_switch_portsvcap_pipe1_axis_switch_0: ports {
			#address-cells = <1>;
			#size-cells = <0>;
			axis_switch_port0vcap_pipe1_axis_switch_0: port@0 {
				reg = <0>;
				vcap_pipe1_mipi_csi2_rx_subsyst_0vcap_pipe1_mipi_csi2_rx_subsyst_0: endpoint {
					remote-endpoint = <&mipi_csirx_outvcap_pipe1_mipi_csi2_rx_subsyst_0>;
				};
			};
		};
	};
	vcap_pipe2_axis_switch_0: axis_switch_vcap_pipe2_axis_switch_0@0 {
		compatible = "xlnx,axis-switch-1.1";
		xlnx,routing-mode = <0>;
		xlnx,num-si-slots = <1>;
		xlnx,num-mi-slots = <4>;
		axis_switch_portsvcap_pipe2_axis_switch_0: ports {
			#address-cells = <1>;
			#size-cells = <0>;
			axis_switch_port0vcap_pipe2_axis_switch_0: port@0 {
				reg = <0>;
				vcap_pipe2_mipi_csi2_rx_subsyst_0vcap_pipe2_mipi_csi2_rx_subsyst_0: endpoint {
					remote-endpoint = <&mipi_csirx_outvcap_pipe2_mipi_csi2_rx_subsyst_0>;
				};
			};
		};
	};
	vcap_pipe3_axis_switch_0: axis_switch_vcap_pipe3_axis_switch_0@0 {
		compatible = "xlnx,axis-switch-1.1";
		xlnx,routing-mode = <0>;
		xlnx,num-si-slots = <1>;
		xlnx,num-mi-slots = <4>;
		axis_switch_portsvcap_pipe3_axis_switch_0: ports {
			#address-cells = <1>;
			#size-cells = <0>;
			axis_switch_port0vcap_pipe3_axis_switch_0: port@0 {
				reg = <0>;
				vcap_pipe3_mipi_csi2_rx_subsyst_0vcap_pipe3_mipi_csi2_rx_subsyst_0: endpoint {
					remote-endpoint = <&mipi_csirx_outvcap_pipe3_mipi_csi2_rx_subsyst_0>;
				};
			};
		};
	};
};
